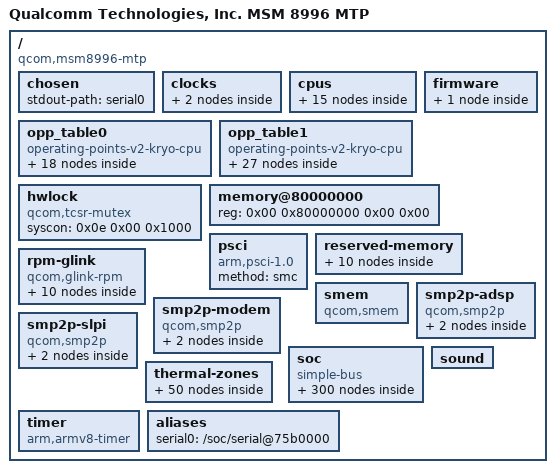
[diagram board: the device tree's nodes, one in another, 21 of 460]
/dts-v1/;

/ {
	interrupt-parent = <0x01>;
	#address-cells = <0x02>;
	#size-cells = <0x02>;
	model = "Qualcomm Technologies, Inc. MSM 8996 MTP";
	compatible = "qcom,msm8996-mtp";

	chosen {
		stdout-path = "serial0";
	};

	clocks {

		xo-board {
			compatible = "fixed-clock";
			#clock-cells = <0x00>;
			clock-frequency = <0x124f800>;
			clock-output-names = "xo_board";
			phandle = <0x1d>;
		};

		sleep-clk {
			compatible = "fixed-clock";
			#clock-cells = <0x00>;
			clock-frequency = <0x7ffc>;
			clock-output-names = "sleep_clk";
			phandle = <0x78>;
		};
	};

	cpus {
		#address-cells = <0x02>;
		#size-cells = <0x00>;

		cpu@0 {
			device_type = "cpu";
			compatible = "qcom,kryo";
			reg = <0x00 0x00>;
			enable-method = "psci";
			cpu-idle-states = <0x02>;
			capacity-dmips-mhz = <0x400>;
			clocks = <0x03 0x00>;
			operating-points-v2 = <0x04>;
			#cooling-cells = <0x02>;
			next-level-cache = <0x05>;
			phandle = <0x08>;

			l2-cache {
				compatible = "cache";
				cache-level = <0x02>;
				phandle = <0x05>;
			};
		};

		cpu@1 {
			device_type = "cpu";
			compatible = "qcom,kryo";
			reg = <0x00 0x01>;
			enable-method = "psci";
			cpu-idle-states = <0x02>;
			capacity-dmips-mhz = <0x400>;
			clocks = <0x03 0x00>;
			operating-points-v2 = <0x04>;
			#cooling-cells = <0x02>;
			next-level-cache = <0x05>;
			phandle = <0x09>;
		};

		cpu@100 {
			device_type = "cpu";
			compatible = "qcom,kryo";
			reg = <0x00 0x100>;
			enable-method = "psci";
			cpu-idle-states = <0x02>;
			capacity-dmips-mhz = <0x400>;
			clocks = <0x03 0x01>;
			operating-points-v2 = <0x06>;
			#cooling-cells = <0x02>;
			next-level-cache = <0x07>;
			phandle = <0x0a>;

			l2-cache {
				compatible = "cache";
				cache-level = <0x02>;
				phandle = <0x07>;
			};
		};

		cpu@101 {
			device_type = "cpu";
			compatible = "qcom,kryo";
			reg = <0x00 0x101>;
			enable-method = "psci";
			cpu-idle-states = <0x02>;
			capacity-dmips-mhz = <0x400>;
			clocks = <0x03 0x01>;
			operating-points-v2 = <0x06>;
			#cooling-cells = <0x02>;
			next-level-cache = <0x07>;
			phandle = <0x0b>;
		};

		cpu-map {

			cluster0 {

				core0 {
					cpu = <0x08>;
				};

				core1 {
					cpu = <0x09>;
				};
			};

			cluster1 {

				core0 {
					cpu = <0x0a>;
				};

				core1 {
					cpu = <0x0b>;
				};
			};
		};

		idle-states {
			entry-method = "psci";

			cpu-sleep-0 {
				compatible = "arm,idle-state";
				idle-state-name = "standalone-power-collapse";
				arm,psci-suspend-param = <0x04>;
				entry-latency-us = <0x82>;
				exit-latency-us = <0x50>;
				min-residency-us = <0x12c>;
				phandle = <0x02>;
			};
		};
	};

	opp_table0 {
		compatible = "operating-points-v2-kryo-cpu";
		nvmem-cells = <0x0c>;
		opp-shared;
		phandle = <0x04>;

		opp-307200000 {
			opp-hz = <0x00 0x124f8000>;
			opp-supported-hw = <0x07>;
			clock-latency-ns = <0x30d40>;
		};

		opp-422400000 {
			opp-hz = <0x00 0x192d5000>;
			opp-supported-hw = <0x07>;
			clock-latency-ns = <0x30d40>;
		};

		opp-480000000 {
			opp-hz = <0x00 0x1c9c3800>;
			opp-supported-hw = <0x07>;
			clock-latency-ns = <0x30d40>;
		};

		opp-556800000 {
			opp-hz = <0x00 0x21301800>;
			opp-supported-hw = <0x07>;
			clock-latency-ns = <0x30d40>;
		};

		opp-652800000 {
			opp-hz = <0x00 0x26e8f000>;
			opp-supported-hw = <0x07>;
			clock-latency-ns = <0x30d40>;
		};

		opp-729600000 {
			opp-hz = <0x00 0x2b7cd000>;
			opp-supported-hw = <0x07>;
			clock-latency-ns = <0x30d40>;
		};

		opp-844800000 {
			opp-hz = <0x00 0x325aa000>;
			opp-supported-hw = <0x07>;
			clock-latency-ns = <0x30d40>;
		};

		opp-960000000 {
			opp-hz = <0x00 0x39387000>;
			opp-supported-hw = <0x07>;
			clock-latency-ns = <0x30d40>;
		};

		opp-1036800000 {
			opp-hz = <0x00 0x3dcc5000>;
			opp-supported-hw = <0x07>;
			clock-latency-ns = <0x30d40>;
		};

		opp-1113600000 {
			opp-hz = <0x00 0x42603000>;
			opp-supported-hw = <0x07>;
			clock-latency-ns = <0x30d40>;
		};

		opp-1190400000 {
			opp-hz = <0x00 0x46f41000>;
			opp-supported-hw = <0x07>;
			clock-latency-ns = <0x30d40>;
		};

		opp-1228800000 {
			opp-hz = <0x00 0x493e0000>;
			opp-supported-hw = <0x07>;
			clock-latency-ns = <0x30d40>;
		};

		opp-1324800000 {
			opp-hz = <0x00 0x4ef6d800>;
			opp-supported-hw = <0x05>;
			clock-latency-ns = <0x30d40>;
		};

		opp-1363200000 {
			opp-hz = <0x00 0x5140c800>;
			opp-supported-hw = <0x02>;
			clock-latency-ns = <0x30d40>;
		};

		opp-1401600000 {
			opp-hz = <0x00 0x538ab800>;
			opp-supported-hw = <0x05>;
			clock-latency-ns = <0x30d40>;
		};

		opp-1478400000 {
			opp-hz = <0x00 0x581e9800>;
			opp-supported-hw = <0x01>;
			clock-latency-ns = <0x30d40>;
		};

		opp-1497600000 {
			opp-hz = <0x00 0x59439000>;
			opp-supported-hw = <0x04>;
			clock-latency-ns = <0x30d40>;
		};

		opp-1593600000 {
			opp-hz = <0x00 0x5efc6800>;
			opp-supported-hw = <0x01>;
			clock-latency-ns = <0x30d40>;
		};
	};

	opp_table1 {
		compatible = "operating-points-v2-kryo-cpu";
		nvmem-cells = <0x0c>;
		opp-shared;
		phandle = <0x06>;

		opp-307200000 {
			opp-hz = <0x00 0x124f8000>;
			opp-supported-hw = <0x07>;
			clock-latency-ns = <0x30d40>;
		};

		opp-403200000 {
			opp-hz = <0x00 0x18085800>;
			opp-supported-hw = <0x07>;
			clock-latency-ns = <0x30d40>;
		};

		opp-480000000 {
			opp-hz = <0x00 0x1c9c3800>;
			opp-supported-hw = <0x07>;
			clock-latency-ns = <0x30d40>;
		};

		opp-556800000 {
			opp-hz = <0x00 0x21301800>;
			opp-supported-hw = <0x07>;
			clock-latency-ns = <0x30d40>;
		};

		opp-652800000 {
			opp-hz = <0x00 0x26e8f000>;
			opp-supported-hw = <0x07>;
			clock-latency-ns = <0x30d40>;
		};

		opp-729600000 {
			opp-hz = <0x00 0x2b7cd000>;
			opp-supported-hw = <0x07>;
			clock-latency-ns = <0x30d40>;
		};

		opp-806400000 {
			opp-hz = <0x00 0x3010b000>;
			opp-supported-hw = <0x07>;
			clock-latency-ns = <0x30d40>;
		};

		opp-883200000 {
			opp-hz = <0x00 0x34a49000>;
			opp-supported-hw = <0x07>;
			clock-latency-ns = <0x30d40>;
		};

		opp-940800000 {
			opp-hz = <0x00 0x38137800>;
			opp-supported-hw = <0x07>;
			clock-latency-ns = <0x30d40>;
		};

		opp-1036800000 {
			opp-hz = <0x00 0x3dcc5000>;
			opp-supported-hw = <0x07>;
			clock-latency-ns = <0x30d40>;
		};

		opp-1113600000 {
			opp-hz = <0x00 0x42603000>;
			opp-supported-hw = <0x07>;
			clock-latency-ns = <0x30d40>;
		};

		opp-1190400000 {
			opp-hz = <0x00 0x46f41000>;
			opp-supported-hw = <0x07>;
			clock-latency-ns = <0x30d40>;
		};

		opp-1248000000 {
			opp-hz = <0x00 0x4a62f800>;
			opp-supported-hw = <0x07>;
			clock-latency-ns = <0x30d40>;
		};

		opp-1324800000 {
			opp-hz = <0x00 0x4ef6d800>;
			opp-supported-hw = <0x07>;
			clock-latency-ns = <0x30d40>;
		};

		opp-1401600000 {
			opp-hz = <0x00 0x538ab800>;
			opp-supported-hw = <0x07>;
			clock-latency-ns = <0x30d40>;
		};

		opp-1478400000 {
			opp-hz = <0x00 0x581e9800>;
			opp-supported-hw = <0x07>;
			clock-latency-ns = <0x30d40>;
		};

		opp-1555200000 {
			opp-hz = <0x00 0x5cb27800>;
			opp-supported-hw = <0x07>;
			clock-latency-ns = <0x30d40>;
		};

		opp-1632000000 {
			opp-hz = <0x00 0x61465800>;
			opp-supported-hw = <0x07>;
			clock-latency-ns = <0x30d40>;
		};

		opp-1708800000 {
			opp-hz = <0x00 0x65da3800>;
			opp-supported-hw = <0x07>;
			clock-latency-ns = <0x30d40>;
		};

		opp-1785600000 {
			opp-hz = <0x00 0x6a6e1800>;
			opp-supported-hw = <0x07>;
			clock-latency-ns = <0x30d40>;
		};

		opp-1804800000 {
			opp-hz = <0x00 0x6b931000>;
			opp-supported-hw = <0x06>;
			clock-latency-ns = <0x30d40>;
		};

		opp-1824000000 {
			opp-hz = <0x00 0x6cb80800>;
			opp-supported-hw = <0x01>;
			clock-latency-ns = <0x30d40>;
		};

		opp-1900800000 {
			opp-hz = <0x00 0x714be800>;
			opp-supported-hw = <0x04>;
			clock-latency-ns = <0x30d40>;
		};

		opp-1920000000 {
			opp-hz = <0x00 0x7270e000>;
			opp-supported-hw = <0x01>;
			clock-latency-ns = <0x30d40>;
		};

		opp-1996800000 {
			opp-hz = <0x00 0x7704c000>;
			opp-supported-hw = <0x01>;
			clock-latency-ns = <0x30d40>;
		};

		opp-2073600000 {
			opp-hz = <0x00 0x7b98a000>;
			opp-supported-hw = <0x01>;
			clock-latency-ns = <0x30d40>;
		};

		opp-2150400000 {
			opp-hz = <0x00 0x802c8000>;
			opp-supported-hw = <0x01>;
			clock-latency-ns = <0x30d40>;
		};
	};

	firmware {

		scm {
			compatible = "qcom,scm-msm8996";
			qcom,dload-mode = <0x0d 0x13000>;
		};
	};

	hwlock {
		compatible = "qcom,tcsr-mutex";
		syscon = <0x0e 0x00 0x1000>;
		#hwlock-cells = <0x01>;
		phandle = <0x13>;
	};

	memory@80000000 {
		device_type = "memory";
		reg = <0x00 0x80000000 0x00 0x00>;
	};

	psci {
		compatible = "arm,psci-1.0";
		method = "smc";
	};

	reserved-memory {
		#address-cells = <0x02>;
		#size-cells = <0x02>;
		ranges;

		mba@91500000 {
			reg = <0x00 0x91500000 0x00 0x200000>;
			no-map;
			phandle = <0x79>;
		};

		slpi@90b00000 {
			reg = <0x00 0x90b00000 0x00 0xa00000>;
			no-map;
			phandle = <0x7a>;
		};

		venus@90400000 {
			reg = <0x00 0x90400000 0x00 0x700000>;
			no-map;
			phandle = <0x33>;
		};

		adsp@8ea00000 {
			reg = <0x00 0x8ea00000 0x00 0x1a00000>;
			no-map;
			phandle = <0x6f>;
		};

		mpss@88800000 {
			reg = <0x00 0x88800000 0x00 0x6200000>;
			no-map;
			phandle = <0x7b>;
		};

		smem-mem@86000000 {
			reg = <0x00 0x86000000 0x00 0x200000>;
			no-map;
			phandle = <0x12>;
		};

		memory@85800000 {
			reg = <0x00 0x85800000 0x00 0x800000>;
			no-map;
		};

		memory@86200000 {
			reg = <0x00 0x86200000 0x00 0x2600000>;
			no-map;
		};

		rmtfs@86700000 {
			compatible = "qcom,rmtfs-mem";
			size = <0x00 0x200000>;
			alloc-ranges = <0x00 0xa0000000 0x00 0x2000000>;
			no-map;
			qcom,client-id = <0x01>;
			qcom,vmid = <0x0f>;
		};

		gpu@8f200000 {
			compatible = "shared-dma-pool";
			reg = <0x00 0x90b00000 0x00 0xa00000>;
			no-map;
			phandle = <0x22>;
		};
	};

	rpm-glink {
		compatible = "qcom,glink-rpm";
		interrupts = <0x00 0xa8 0x01>;
		qcom,rpm-msg-ram = <0x0f>;
		mboxes = <0x10 0x00>;

		rpm-requests {
			compatible = "qcom,rpm-msm8996";
			qcom,glink-channels = "rpm_requests";
			phandle = <0x7c>;

			qcom,rpmcc {
				compatible = "qcom,rpmcc-msm8996";
				#clock-cells = <0x01>;
				phandle = <0x15>;
			};

			power-controller {
				compatible = "qcom,msm8996-rpmpd";
				#power-domain-cells = <0x01>;
				operating-points-v2 = <0x11>;
				phandle = <0x71>;

				opp-table {
					compatible = "operating-points-v2";
					phandle = <0x11>;

					opp1 {
						opp-level = <0x01>;
						phandle = <0x7d>;
					};

					opp2 {
						opp-level = <0x02>;
						phandle = <0x7e>;
					};

					opp3 {
						opp-level = <0x03>;
						phandle = <0x7f>;
					};

					opp4 {
						opp-level = <0x04>;
						phandle = <0x80>;
					};

					opp5 {
						opp-level = <0x05>;
						phandle = <0x81>;
					};

					opp6 {
						opp-level = <0x06>;
						phandle = <0x82>;
					};
				};
			};
		};
	};

	smem {
		compatible = "qcom,smem";
		memory-region = <0x12>;
		hwlocks = <0x13 0x03>;
	};

	smp2p-adsp {
		compatible = "qcom,smp2p";
		qcom,smem = <0x1bb 0x1ad>;
		interrupts = <0x00 0x9e 0x01>;
		mboxes = <0x10 0x0a>;
		qcom,local-pid = <0x00>;
		qcom,remote-pid = <0x02>;

		master-kernel {
			qcom,entry-name = "master-kernel";
			#qcom,smem-state-cells = <0x01>;
			phandle = <0x70>;
		};

		slave-kernel {
			qcom,entry-name = "slave-kernel";
			interrupt-controller;
			#interrupt-cells = <0x02>;
			phandle = <0x6e>;
		};
	};

	smp2p-modem {
		compatible = "qcom,smp2p";
		qcom,smem = <0x1b3 0x1ac>;
		interrupts = <0x00 0x1c3 0x01>;
		mboxes = <0x10 0x0e>;
		qcom,local-pid = <0x00>;
		qcom,remote-pid = <0x01>;

		master-kernel {
			qcom,entry-name = "master-kernel";
			#qcom,smem-state-cells = <0x01>;
			phandle = <0x83>;
		};

		slave-kernel {
			qcom,entry-name = "slave-kernel";
			interrupt-controller;
			#interrupt-cells = <0x02>;
			phandle = <0x84>;
		};
	};

	smp2p-slpi {
		compatible = "qcom,smp2p";
		qcom,smem = <0x1e1 0x1ae>;
		interrupts = <0x00 0xb2 0x01>;
		mboxes = <0x10 0x1a>;
		qcom,local-pid = <0x00>;
		qcom,remote-pid = <0x03>;

		slave-kernel {
			qcom,entry-name = "slave-kernel";
			interrupt-controller;
			#interrupt-cells = <0x02>;
			phandle = <0x85>;
		};

		master-kernel {
			qcom,entry-name = "master-kernel";
			#qcom,smem-state-cells = <0x01>;
			phandle = <0x86>;
		};
	};

	soc {
		#address-cells = <0x01>;
		#size-cells = <0x01>;
		ranges = <0x00 0x00 0x00 0xffffffff>;
		compatible = "simple-bus";
		phandle = <0x87>;

		phy@34000 {
			compatible = "qcom,msm8996-qmp-pcie-phy";
			reg = <0x34000 0x488>;
			#clock-cells = <0x01>;
			#address-cells = <0x01>;
			#size-cells = <0x01>;
			ranges;
			clocks = <0x14 0xc0 0x14 0xbf 0x14 0xd8>;
			clock-names = "aux\0cfg_ahb\0ref";
			resets = <0x14 0x55 0x14 0x65 0x14 0x66>;
			reset-names = "phy\0common\0cfg";
			status = "disabled";
			phandle = <0x88>;

			phy@35000 {
				reg = <0x35000 0x130 0x35200 0x200 0x35400 0x1dc>;
				#phy-cells = <0x00>;
				clock-output-names = "pcie_0_pipe_clk_src";
				clocks = <0x14 0xb4>;
				clock-names = "pipe0";
				resets = <0x14 0x50>;
				reset-names = "lane0";
				phandle = <0x24>;
			};

			phy@36000 {
				reg = <0x36000 0x130 0x36200 0x200 0x36400 0x1dc>;
				#phy-cells = <0x00>;
				clock-output-names = "pcie_1_pipe_clk_src";
				clocks = <0x14 0xb9>;
				clock-names = "pipe1";
				resets = <0x14 0x52>;
				reset-names = "lane1";
				phandle = <0x27>;
			};

			phy@37000 {
				reg = <0x37000 0x130 0x37200 0x200 0x37400 0x1dc>;
				#phy-cells = <0x00>;
				clock-output-names = "pcie_2_pipe_clk_src";
				clocks = <0x14 0xbe>;
				clock-names = "pipe2";
				resets = <0x14 0x54>;
				reset-names = "lane2";
				phandle = <0x2a>;
			};
		};

		sram@68000 {
			compatible = "qcom,rpm-msg-ram";
			reg = <0x68000 0x6000>;
			phandle = <0x0f>;
		};

		qfprom@74000 {
			compatible = "qcom,qfprom";
			reg = <0x74000 0x8ff>;
			#address-cells = <0x01>;
			#size-cells = <0x01>;

			hstx_trim@24e {
				reg = <0x24e 0x02>;
				bits = <0x05 0x04>;
				phandle = <0x54>;
			};

			hstx_trim@24f {
				reg = <0x24f 0x01>;
				bits = <0x01 0x04>;
				phandle = <0x55>;
			};

			speedbin@133 {
				reg = <0x133 0x01>;
				bits = <0x05 0x03>;
				phandle = <0x0c>;
			};
		};

		rng@83000 {
			compatible = "qcom,prng-ee";
			reg = <0x83000 0x1000>;
			clocks = <0x14 0x98>;
			clock-names = "core";
			phandle = <0x89>;
		};

		clock-controller@300000 {
			compatible = "qcom,gcc-msm8996";
			#clock-cells = <0x01>;
			#reset-cells = <0x01>;
			#power-domain-cells = <0x01>;
			reg = <0x300000 0x90000>;
			clocks = <0x15 0x4a>;
			clock-names = "cxo2";
			phandle = <0x14>;
		};

		thermal-sensor@4a9000 {
			compatible = "qcom,msm8996-tsens\0qcom,tsens-v2";
			reg = <0x4a9000 0x1000 0x4a8000 0x1000>;
			#qcom,sensors = <0x0d>;
			interrupts = <0x00 0x1ca 0x04 0x00 0x1bd 0x04>;
			interrupt-names = "uplow\0critical";
			#thermal-sensor-cells = <0x01>;
			phandle = <0x73>;
		};

		thermal-sensor@4ad000 {
			compatible = "qcom,msm8996-tsens\0qcom,tsens-v2";
			reg = <0x4ad000 0x1000 0x4ac000 0x1000>;
			#qcom,sensors = <0x08>;
			interrupts = <0x00 0xb8 0x04 0x00 0x1ae 0x04>;
			interrupt-names = "uplow\0critical";
			#thermal-sensor-cells = <0x01>;
			phandle = <0x74>;
		};

		syscon@740000 {
			compatible = "syscon";
			reg = <0x740000 0x40000>;
			phandle = <0x0e>;
		};

		syscon@7a0000 {
			compatible = "qcom,tcsr-msm8996\0syscon";
			reg = <0x7a0000 0x18000>;
			phandle = <0x0d>;
		};

		clock-controller@8c0000 {
			compatible = "qcom,mmcc-msm8996";
			#clock-cells = <0x01>;
			#reset-cells = <0x01>;
			#power-domain-cells = <0x01>;
			reg = <0x8c0000 0x40000>;
			assigned-clocks = <0x16 0x0f 0x16 0x03 0x16 0x07 0x16 0x09 0x16 0x0b>;
			assigned-clock-rates = <0x25317c00 0x30479e80 0x3a699d00 0x39387000 0x312c8040>;
			phandle = <0x16>;
		};

		mdss@900000 {
			compatible = "qcom,mdss";
			reg = <0x900000 0x1000 0x9b0000 0x1040 0x9b8000 0x1040>;
			reg-names = "mdss_phys\0vbif_phys\0vbif_nrt_phys";
			power-domains = <0x16 0x0d>;
			interrupts = <0x00 0x53 0x04>;
			interrupt-controller;
			#interrupt-cells = <0x01>;
			clocks = <0x16 0x74>;
			clock-names = "iface";
			#address-cells = <0x01>;
			#size-cells = <0x01>;
			ranges;
			status = "disabled";
			phandle = <0x17>;

			mdp@901000 {
				compatible = "qcom,mdp5";
				reg = <0x901000 0x90000>;
				reg-names = "mdp_phys";
				interrupt-parent = <0x17>;
				interrupts = <0x00 0x04>;
				clocks = <0x16 0x74 0x16 0x76 0x16 0x79 0x16 0x5c 0x16 0x7b>;
				clock-names = "iface\0bus\0core\0iommu\0vsync";
				iommus = <0x18 0x00>;
				assigned-clocks = <0x16 0x79 0x16 0x7b>;
				assigned-clock-rates = <0x11e1a300 0x124f800>;
				phandle = <0x8a>;

				ports {
					#address-cells = <0x01>;
					#size-cells = <0x00>;

					port@0 {
						reg = <0x00>;

						endpoint {
							remote-endpoint = <0x19>;
							phandle = <0x1f>;
						};
					};

					port@1 {
						reg = <0x01>;

						endpoint {
							remote-endpoint = <0x1a>;
							phandle = <0x1c>;
						};
					};
				};
			};

			dsi@994000 {
				compatible = "qcom,mdss-dsi-ctrl";
				reg = <0x994000 0x400>;
				reg-names = "dsi_ctrl";
				interrupt-parent = <0x17>;
				interrupts = <0x04 0x04>;
				clocks = <0x16 0x79 0x16 0x7d 0x16 0x74 0x16 0x76 0x16 0x41 0x16 0x77 0x16 0x7f>;
				clock-names = "mdp_core\0byte\0iface\0bus\0core_mmss\0pixel\0core";
				phys = <0x1b>;
				phy-names = "dsi";
				status = "disabled";
				#address-cells = <0x01>;
				#size-cells = <0x00>;
				phandle = <0x8b>;

				ports {
					#address-cells = <0x01>;
					#size-cells = <0x00>;

					port@0 {
						reg = <0x00>;

						endpoint {
							remote-endpoint = <0x1c>;
							phandle = <0x1a>;
						};
					};

					port@1 {
						reg = <0x01>;

						endpoint {
							phandle = <0x8c>;
						};
					};
				};
			};

			dsi-phy@994400 {
				compatible = "qcom,dsi-phy-14nm";
				reg = <0x994400 0x100 0x994500 0x300 0x994800 0x188>;
				reg-names = "dsi_phy\0dsi_phy_lane\0dsi_pll";
				#clock-cells = <0x01>;
				#phy-cells = <0x00>;
				clocks = <0x16 0x74 0x1d>;
				clock-names = "iface\0ref";
				status = "disabled";
				phandle = <0x1b>;
			};

			hdmi-tx@9a0000 {
				compatible = "qcom,hdmi-tx-8996";
				reg = <0x9a0000 0x50c 0x70000 0x6158 0x9e0000 0xfff>;
				reg-names = "core_physical\0qfprom_physical\0hdcp_physical";
				interrupt-parent = <0x17>;
				interrupts = <0x08 0x04>;
				clocks = <0x16 0x79 0x16 0x74 0x16 0x7c 0x16 0x75 0x16 0x7a>;
				clock-names = "mdp_core\0iface\0core\0alt_iface\0extp";
				phys = <0x1e>;
				phy-names = "hdmi_phy";
				#sound-dai-cells = <0x01>;
				status = "okay";
				phandle = <0x8d>;

				ports {
					#address-cells = <0x01>;
					#size-cells = <0x00>;

					port@0 {
						reg = <0x00>;

						endpoint {
							remote-endpoint = <0x1f>;
							phandle = <0x19>;
						};
					};
				};
			};

			hdmi-phy@9a0600 {
				#phy-cells = <0x00>;
				compatible = "qcom,hdmi-phy-8996";
				reg = <0x9a0600 0x1c4 0x9a0a00 0x124 0x9a0c00 0x124 0x9a0e00 0x124 0x9a1000 0x124 0x9a1200 0xc8>;
				reg-names = "hdmi_pll\0hdmi_tx_l0\0hdmi_tx_l1\0hdmi_tx_l2\0hdmi_tx_l3\0hdmi_phy";
				clocks = <0x16 0x74 0x14 0xd6>;
				clock-names = "iface\0ref";
				status = "okay";
				phandle = <0x1e>;
			};
		};

		gpu@b00000 {
			compatible = "qcom,adreno-530.2\0qcom,adreno";
			#stream-id-cells = <0x10>;
			reg = <0xb00000 0x3f000>;
			reg-names = "kgsl_3d0_reg_memory";
			interrupts = <0x00 0x12c 0x04>;
			clocks = <0x16 0x66 0x16 0x68 0x16 0x67 0x14 0xa8 0x14 0x5a>;
			clock-names = "core\0iface\0rbbmtimer\0mem\0mem_iface";
			power-domains = <0x16 0x0e>;
			iommus = <0x20 0x00>;
			nvmem-cells = <0x0c>;
			nvmem-cell-names = "speed_bin";
			operating-points-v2 = <0x21>;
			status = "disabled";
			#cooling-cells = <0x02>;
			phandle = <0x76>;

			opp-table {
				compatible = "operating-points-v2";
				phandle = <0x21>;

				opp-624000000 {
					opp-hz = <0x00 0x25317c00>;
					opp-supported-hw = <0x09>;
				};

				opp-560000000 {
					opp-hz = <0x00 0x2160ec00>;
					opp-supported-hw = <0x0d>;
				};

				opp-510000000 {
					opp-hz = <0x00 0x1e65fb80>;
					opp-supported-hw = <0xff>;
				};

				opp-401800000 {
					opp-hz = <0x00 0x17f2fb40>;
					opp-supported-hw = <0xff>;
				};

				opp-315000000 {
					opp-hz = <0x00 0x12c684c0>;
					opp-supported-hw = <0xff>;
				};

				opp-214000000 {
					opp-hz = <0x00 0xcc16180>;
					opp-supported-hw = <0xff>;
				};

				opp-133000000 {
					opp-hz = <0x00 0x7ed6b40>;
					opp-supported-hw = <0xff>;
				};
			};

			zap-shader {
				memory-region = <0x22>;
			};
		};

		pinctrl@1010000 {
			compatible = "qcom,msm8996-pinctrl";
			reg = <0x1010000 0x300000>;
			interrupts = <0x00 0xd0 0x04>;
			gpio-controller;
			gpio-ranges = <0x23 0x00 0x00 0x96>;
			#gpio-cells = <0x02>;
			interrupt-controller;
			#interrupt-cells = <0x02>;
			phandle = <0x23>;

			blsp1-spi1-default {
				phandle = <0x5b>;

				spi {
					pins = "gpio0\0gpio1\0gpio3";
					function = "blsp_spi1";
					drive-strength = <0x0c>;
					bias-disable;
				};

				cs {
					pins = "gpio2";
					function = "gpio";
					drive-strength = <0x10>;
					bias-disable;
					output-high;
				};
			};

			blsp1-spi1-sleep {
				pins = "gpio0\0gpio1\0gpio2\0gpio3";
				function = "gpio";
				drive-strength = <0x02>;
				bias-pull-down;
				phandle = <0x5c>;
			};

			blsp2-uart1-2pins {
				pins = "gpio4\0gpio5";
				function = "blsp_uart8";
				drive-strength = <0x10>;
				bias-disable;
				phandle = <0x8e>;
			};

			blsp2-uart1-2pins-sleep {
				pins = "gpio4\0gpio5";
				function = "gpio";
				drive-strength = <0x02>;
				bias-disable;
				phandle = <0x8f>;
			};

			blsp2-i2c2 {
				pins = "gpio6\0gpio7";
				function = "blsp_i2c8";
				drive-strength = <0x10>;
				bias-disable;
				phandle = <0x62>;
			};

			blsp2-i2c2-sleep {
				pins = "gpio6\0gpio7";
				function = "gpio";
				drive-strength = <0x02>;
				bias-disable;
				phandle = <0x63>;
			};

			cci0-default {
				pins = "gpio17\0gpio18";
				function = "cci_i2c";
				drive-strength = <0x10>;
				bias-disable;
				phandle = <0x30>;
			};

			camera-rear-default {
				phandle = <0x90>;

				mclk0 {
					pins = "gpio13";
					function = "cam_mclk";
					drive-strength = <0x10>;
					bias-disable;
					phandle = <0x91>;
				};

				rst {
					pins = "gpio25";
					function = "gpio";
					drive-strength = <0x10>;
					bias-disable;
					phandle = <0x92>;
				};

				pwdn {
					pins = "gpio26";
					function = "gpio";
					drive-strength = <0x10>;
					bias-disable;
					phandle = <0x93>;
				};
			};

			cci1-default {
				pins = "gpio19\0gpio20";
				function = "cci_i2c";
				drive-strength = <0x10>;
				bias-disable;
				phandle = <0x31>;
			};

			camera-board-default {
				phandle = <0x94>;

				mclk1 {
					pins = "gpio14";
					function = "cam_mclk";
					drive-strength = <0x10>;
					bias-disable;
				};

				pwdn {
					pins = "gpio98";
					function = "gpio";
					drive-strength = <0x10>;
					bias-disable;
				};

				rst {
					pins = "gpio104";
					function = "gpio";
					drive-strength = <0x10>;
					bias-disable;
				};
			};

			camera-front-default {
				phandle = <0x95>;

				mclk2 {
					pins = "gpio15";
					function = "cam_mclk";
					drive-strength = <0x10>;
					bias-disable;
					phandle = <0x96>;
				};

				rst {
					pins = "gpio23";
					function = "gpio";
					drive-strength = <0x10>;
					bias-disable;
					phandle = <0x97>;
				};

				pwdn {
					pins = "gpio133";
					function = "gpio";
					drive-strength = <0x10>;
					bias-disable;
				};
			};

			pcie0-state-on {
				phandle = <0x25>;

				perst {
					pins = "gpio35";
					function = "gpio";
					drive-strength = <0x02>;
					bias-pull-down;
				};

				clkreq {
					pins = "gpio36";
					function = "pci_e0";
					drive-strength = <0x02>;
					bias-pull-up;
				};

				wake {
					pins = "gpio37";
					function = "gpio";
					drive-strength = <0x02>;
					bias-pull-up;
				};
			};

			pcie0-state-off {
				phandle = <0x26>;

				perst {
					pins = "gpio35";
					function = "gpio";
					drive-strength = <0x02>;
					bias-pull-down;
				};

				clkreq {
					pins = "gpio36";
					function = "gpio";
					drive-strength = <0x02>;
					bias-disable;
				};

				wake {
					pins = "gpio37";
					function = "gpio";
					drive-strength = <0x02>;
					bias-disable;
				};
			};

			blsp1-i2c2-default {
				pins = "gpio47\0gpio48";
				function = "blsp_i2c3";
				drive-strength = <0x10>;
				bias-disable = <0x00>;
				phandle = <0x5d>;
			};

			blsp1-i2c2-sleep {
				pins = "gpio47\0gpio48";
				function = "gpio";
				drive-strength = <0x02>;
				bias-disable = <0x00>;
				phandle = <0x5e>;
			};

			blsp2-uart2-4pins {
				pins = "gpio49\0gpio50\0gpio51\0gpio52";
				function = "blsp_uart9";
				drive-strength = <0x10>;
				bias-disable;
				phandle = <0x98>;
			};

			blsp2-uart2-4pins-sleep {
				pins = "gpio49\0gpio50\0gpio51\0gpio52";
				function = "blsp_uart9";
				drive-strength = <0x02>;
				bias-disable;
				phandle = <0x99>;
			};

			wcd-intr-default {
				pins = "gpio54";
				function = "gpio";
				drive-strength = <0x02>;
				bias-pull-down;
				input-enable;
				phandle = <0x6c>;
			};

			blsp2-i2c1 {
				pins = "gpio55\0gpio56";
				function = "blsp_i2c7";
				drive-strength = <0x10>;
				bias-disable;
				phandle = <0x5f>;
			};

			blsp2-i2c0-sleep {
				pins = "gpio55\0gpio56";
				function = "gpio";
				drive-strength = <0x02>;
				bias-disable;
				phandle = <0x60>;
			};

			blsp2-i2c5 {
				pins = "gpio60\0gpio61";
				function = "blsp_i2c11";
				drive-strength = <0x02>;
				bias-disable;
				phandle = <0x64>;
			};

			cdc-reset-active {
				pins = "gpio64";
				function = "gpio";
				drive-strength = <0x10>;
				bias-pull-down;
				output-high;
				phandle = <0x6b>;
			};

			cdc-reset-sleep {
				pins = "gpio64";
				function = "gpio";
				drive-strength = <0x10>;
				bias-disable;
				output-low;
				phandle = <0x9a>;
			};

			blsp2-spi5-default {
				phandle = <0x67>;

				spi {
					pins = "gpio85\0gpio86\0gpio88";
					function = "blsp_spi12";
					drive-strength = <0x0c>;
					bias-disable;
				};

				cs {
					pins = "gpio87";
					function = "gpio";
					drive-strength = <0x10>;
					bias-disable;
					output-high;
				};
			};

			blsp2-spi5-sleep {
				pins = "gpio85\0gpio86\0gpio87\0gpio88";
				function = "gpio";
				drive-strength = <0x02>;
				bias-pull-down;
				phandle = <0x68>;
			};

			blsp2-i2c6 {
				pins = "gpio87\0gpio88";
				function = "blsp_i2c12";
				drive-strength = <0x10>;
				bias-disable;
				phandle = <0x65>;
			};

			blsp2-i2c6-sleep {
				pins = "gpio87\0gpio88";
				function = "gpio";
				drive-strength = <0x02>;
				bias-disable;
				phandle = <0x66>;
			};

			pcie1-state-on {
				phandle = <0x28>;

				perst {
					pins = "gpio130";
					function = "gpio";
					drive-strength = <0x02>;
					bias-pull-down;
				};

				clkreq {
					pins = "gpio131";
					function = "pci_e1";
					drive-strength = <0x02>;
					bias-pull-up;
				};

				wake {
					pins = "gpio132";
					function = "gpio";
					drive-strength = <0x02>;
					bias-pull-down;
				};
			};

			pcie1-state-off {
				phandle = <0x29>;

				clkreq {
					pins = "gpio131";
					function = "gpio";
					drive-strength = <0x02>;
					bias-disable;
				};

				wake {
					pins = "gpio132";
					function = "gpio";
					drive-strength = <0x02>;
					bias-disable;
				};
			};

			pcie2-state-on {
				phandle = <0x2b>;

				perst {
					pins = "gpio114";
					function = "gpio";
					drive-strength = <0x02>;
					bias-pull-down;
				};

				clkreq {
					pins = "gpio115";
					function = "pci_e2";
					drive-strength = <0x02>;
					bias-pull-up;
				};

				wake {
					pins = "gpio116";
					function = "gpio";
					drive-strength = <0x02>;
					bias-pull-down;
				};
			};

			pcie2-state-off {
				phandle = <0x2c>;

				clkreq {
					pins = "gpio115";
					function = "gpio";
					drive-strength = <0x02>;
					bias-disable;
				};

				wake {
					pins = "gpio116";
					function = "gpio";
					drive-strength = <0x02>;
					bias-disable;
				};
			};

			sdc1-state-on {
				phandle = <0x56>;

				clk {
					pins = "sdc1_clk";
					bias-disable;
					drive-strength = <0x10>;
				};

				cmd {
					pins = "sdc1_cmd";
					bias-pull-up;
					drive-strength = <0x0a>;
				};

				data {
					pins = "sdc1_data";
					bias-pull-up;
					drive-strength = <0x0a>;
				};

				rclk {
					pins = "sdc1_rclk";
					bias-pull-down;
				};
			};

			sdc1-state-off {
				phandle = <0x57>;

				clk {
					pins = "sdc1_clk";
					bias-disable;
					drive-strength = <0x02>;
				};

				cmd {
					pins = "sdc1_cmd";
					bias-pull-up;
					drive-strength = <0x02>;
				};

				data {
					pins = "sdc1_data";
					bias-pull-up;
					drive-strength = <0x02>;
				};

				rclk {
					pins = "sdc1_rclk";
					bias-pull-down;
				};
			};

			sdc2-clk-on {
				phandle = <0x58>;

				clk {
					pins = "sdc2_clk";
					bias-disable;
					drive-strength = <0x10>;
				};

				cmd {
					pins = "sdc2_cmd";
					bias-pull-up;
					drive-strength = <0x0a>;
				};

				data {
					pins = "sdc2_data";
					bias-pull-up;
					drive-strength = <0x0a>;
				};
			};

			sdc2-clk-off {
				phandle = <0x59>;

				clk {
					pins = "sdc2_clk";
					bias-disable;
					drive-strength = <0x02>;
				};

				cmd {
					pins = "sdc2_cmd";
					bias-pull-up;
					drive-strength = <0x02>;
				};

				data {
					pins = "sdc2_data";
					bias-pull-up;
					drive-strength = <0x02>;
				};
			};
		};

		qcom,spmi@400f000 {
			compatible = "qcom,spmi-pmic-arb";
			reg = <0x400f000 0x1000 0x4400000 0x800000 0x4c00000 0x800000 0x5800000 0x200000 0x400a000 0x2100>;
			reg-names = "core\0chnls\0obsrvr\0intr\0cnfg";
			interrupt-names = "periph_irq";
			interrupts = <0x00 0x146 0x04>;
			qcom,ee = <0x00>;
			qcom,channel = <0x00>;
			#address-cells = <0x02>;
			#size-cells = <0x00>;
			interrupt-controller;
			#interrupt-cells = <0x04>;
			phandle = <0x9b>;
		};

		agnoc@0 {
			power-domains = <0x14 0x00>;
			compatible = "simple-pm-bus";
			#address-cells = <0x01>;
			#size-cells = <0x01>;
			ranges;

			pcie@600000 {
				compatible = "qcom,pcie-msm8996\0snps,dw-pcie";
				status = "disabled";
				power-domains = <0x14 0x05>;
				bus-range = <0x00 0xff>;
				num-lanes = <0x01>;
				reg = <0x600000 0x2000 0xc000000 0xf1d 0xc000f20 0xa8 0xc100000 0x100000>;
				reg-names = "parf\0dbi\0elbi\0config";
				phys = <0x24>;
				phy-names = "pciephy";
				#address-cells = <0x03>;
				#size-cells = <0x02>;
				ranges = <0x1000000 0x00 0xc200000 0xc200000 0x00 0x100000 0x2000000 0x00 0xc300000 0xc300000 0x00 0xd00000>;
				device_type = "pci";
				interrupts = <0x00 0x195 0x04>;
				interrupt-names = "msi";
				#interrupt-cells = <0x01>;
				interrupt-map-mask = <0x00 0x00 0x00 0x07>;
				interrupt-map = <0x00 0x00 0x00 0x01 0x01 0x00 0xf4 0x04 0x00 0x00 0x00 0x02 0x01 0x00 0xf5 0x04 0x00 0x00 0x00 0x03 0x01 0x00 0xf7 0x04 0x00 0x00 0x00 0x04 0x01 0x00 0xf8 0x04>;
				pinctrl-names = "default\0sleep";
				pinctrl-0 = <0x25>;
				pinctrl-1 = <0x26>;
				linux,pci-domain = <0x00>;
				clocks = <0x14 0xb4 0x14 0xb3 0x14 0xb2 0x14 0xb1 0x14 0xb0>;
				clock-names = "pipe\0aux\0cfg\0bus_master\0bus_slave";
				phandle = <0x9c>;
			};

			pcie@608000 {
				compatible = "qcom,pcie-msm8996\0snps,dw-pcie";
				power-domains = <0x14 0x06>;
				bus-range = <0x00 0xff>;
				num-lanes = <0x01>;
				status = "disabled";
				reg = <0x608000 0x2000 0xd000000 0xf1d 0xd000f20 0xa8 0xd100000 0x100000>;
				reg-names = "parf\0dbi\0elbi\0config";
				phys = <0x27>;
				phy-names = "pciephy";
				#address-cells = <0x03>;
				#size-cells = <0x02>;
				ranges = <0x1000000 0x00 0xd200000 0xd200000 0x00 0x100000 0x2000000 0x00 0xd300000 0xd300000 0x00 0xd00000>;
				device_type = "pci";
				interrupts = <0x00 0x19d 0x04>;
				interrupt-names = "msi";
				#interrupt-cells = <0x01>;
				interrupt-map-mask = <0x00 0x00 0x00 0x07>;
				interrupt-map = <0x00 0x00 0x00 0x01 0x01 0x00 0x110 0x04 0x00 0x00 0x00 0x02 0x01 0x00 0x111 0x04 0x00 0x00 0x00 0x03 0x01 0x00 0x112 0x04 0x00 0x00 0x00 0x04 0x01 0x00 0x113 0x04>;
				pinctrl-names = "default\0sleep";
				pinctrl-0 = <0x28>;
				pinctrl-1 = <0x29>;
				linux,pci-domain = <0x01>;
				clocks = <0x14 0xb9 0x14 0xb8 0x14 0xb7 0x14 0xb6 0x14 0xb5>;
				clock-names = "pipe\0aux\0cfg\0bus_master\0bus_slave";
				phandle = <0x9d>;
			};

			pcie@610000 {
				compatible = "qcom,pcie-msm8996\0snps,dw-pcie";
				power-domains = <0x14 0x07>;
				bus-range = <0x00 0xff>;
				num-lanes = <0x01>;
				status = "disabled";
				reg = <0x610000 0x2000 0xe000000 0xf1d 0xe000f20 0xa8 0xe100000 0x100000>;
				reg-names = "parf\0dbi\0elbi\0config";
				phys = <0x2a>;
				phy-names = "pciephy";
				#address-cells = <0x03>;
				#size-cells = <0x02>;
				ranges = <0x1000000 0x00 0xe200000 0xe200000 0x00 0x100000 0x2000000 0x00 0xe300000 0xe300000 0x00 0x1d00000>;
				device_type = "pci";
				interrupts = <0x00 0x1a5 0x04>;
				interrupt-names = "msi";
				#interrupt-cells = <0x01>;
				interrupt-map-mask = <0x00 0x00 0x00 0x07>;
				interrupt-map = <0x00 0x00 0x00 0x01 0x01 0x00 0x8e 0x04 0x00 0x00 0x00 0x02 0x01 0x00 0x8f 0x04 0x00 0x00 0x00 0x03 0x01 0x00 0x90 0x04 0x00 0x00 0x00 0x04 0x01 0x00 0x91 0x04>;
				pinctrl-names = "default\0sleep";
				pinctrl-0 = <0x2b>;
				pinctrl-1 = <0x2c>;
				linux,pci-domain = <0x02>;
				clocks = <0x14 0xbe 0x14 0xbd 0x14 0xbc 0x14 0xbb 0x14 0xba>;
				clock-names = "pipe\0aux\0cfg\0bus_master\0bus_slave";
				phandle = <0x9e>;
			};
		};

		ufshc@624000 {
			compatible = "qcom,ufshc";
			reg = <0x624000 0x2500>;
			interrupts = <0x00 0x109 0x04>;
			phys = <0x2d>;
			phy-names = "ufsphy";
			power-domains = <0x14 0x08>;
			clock-names = "core_clk_src\0core_clk\0bus_clk\0bus_aggr_clk\0iface_clk\0core_clk_unipro_src\0core_clk_unipro\0core_clk_ice\0ref_clk\0tx_lane0_sync_clk\0rx_lane0_sync_clk";
			clocks = <0x14 0x49 0x14 0xc1 0x14 0x52 0x14 0xd1 0x14 0xc2 0x14 0x4a 0x14 0xc8 0x14 0xc9 0x15 0x4a 0x14 0xc5 0x14 0xc6>;
			freq-table-hz = <0x5f5e100 0xbebc200 0x00 0x00 0x00 0x00 0x00 0x00 0x00 0x00 0x8f0d180 0x11e1a300 0x00 0x00 0x00 0x00 0x00 0x00 0x00 0x00 0x00 0x00>;
			lanes-per-direction = <0x01>;
			#reset-cells = <0x01>;
			status = "disabled";
			phandle = <0x2e>;

			ufs_variant {
				compatible = "qcom,ufs_variant";
			};
		};

		phy@627000 {
			compatible = "qcom,msm8996-qmp-ufs-phy";
			reg = <0x627000 0x1c4>;
			#address-cells = <0x01>;
			#size-cells = <0x01>;
			ranges;
			clocks = <0x14 0xd7>;
			clock-names = "ref";
			resets = <0x2e 0x00>;
			reset-names = "ufsphy";
			status = "disabled";
			phandle = <0x9f>;

			phy@627400 {
				reg = <0x627400 0x12c 0x627600 0x200 0x627c00 0x1b4>;
				#phy-cells = <0x00>;
				phandle = <0x2d>;
			};
		};

		camss@a00000 {
			compatible = "qcom,msm8996-camss";
			reg = <0xa34000 0x1000 0xa00030 0x04 0xa35000 0x1000 0xa00038 0x04 0xa36000 0x1000 0xa00040 0x04 0xa30000 0x100 0xa30400 0x100 0xa30800 0x100 0xa30c00 0x100 0xa31000 0x500 0xa00020 0x10 0xa10000 0x1000 0xa14000 0x1000>;
			reg-names = "csiphy0\0csiphy0_clk_mux\0csiphy1\0csiphy1_clk_mux\0csiphy2\0csiphy2_clk_mux\0csid0\0csid1\0csid2\0csid3\0ispif\0csi_clk_mux\0vfe0\0vfe1";
			interrupts = <0x00 0x4e 0x01 0x00 0x4f 0x01 0x00 0x50 0x01 0x00 0x128 0x01 0x00 0x129 0x01 0x00 0x12a 0x01 0x00 0x12b 0x01 0x00 0x135 0x01 0x00 0x13a 0x01 0x00 0x13b 0x01>;
			interrupt-names = "csiphy0\0csiphy1\0csiphy2\0csid0\0csid1\0csid2\0csid3\0ispif\0vfe0\0vfe1";
			power-domains = <0x16 0x08 0x16 0x09>;
			clocks = <0x16 0x81 0x16 0xb9 0x16 0x8c 0x16 0x8d 0x16 0x8e 0x16 0xa6 0x16 0xa5 0x16 0xa7 0x16 0xa9 0x16 0xa8 0x16 0xab 0x16 0xaa 0x16 0xac 0x16 0xae 0x16 0xad 0x16 0xb0 0x16 0xaf 0x16 0xb1 0x16 0xb3 0x16 0xb2 0x16 0xb5 0x16 0xb4 0x16 0xb6 0x16 0xb8 0x16 0xb7 0x16 0x82 0x16 0x99 0x16 0x9f 0x16 0x9b 0x16 0x9a 0x16 0x9c 0x16 0xa0 0x16 0x9e 0x16 0x9d 0x16 0x97 0x16 0x98>;
			clock-names = "top_ahb\0ispif_ahb\0csiphy0_timer\0csiphy1_timer\0csiphy2_timer\0csi0_ahb\0csi0\0csi0_phy\0csi0_pix\0csi0_rdi\0csi1_ahb\0csi1\0csi1_phy\0csi1_pix\0csi1_rdi\0csi2_ahb\0csi2\0csi2_phy\0csi2_pix\0csi2_rdi\0csi3_ahb\0csi3\0csi3_phy\0csi3_pix\0csi3_rdi\0ahb\0vfe0\0csi_vfe0\0vfe0_ahb\0vfe0_stream\0vfe1\0csi_vfe1\0vfe1_ahb\0vfe1_stream\0vfe_ahb\0vfe_axi";
			iommus = <0x2f 0x00 0x2f 0x01 0x2f 0x02 0x2f 0x03>;
			status = "disabled";
			phandle = <0xa0>;

			ports {
				#address-cells = <0x01>;
				#size-cells = <0x00>;
			};
		};

		cci@a0c000 {
			compatible = "qcom,msm8996-cci";
			#address-cells = <0x01>;
			#size-cells = <0x00>;
			reg = <0xa0c000 0x1000>;
			interrupts = <0x00 0x127 0x01>;
			power-domains = <0x16 0x07>;
			clocks = <0x16 0x81 0x16 0x8b 0x16 0x8a 0x16 0x82>;
			clock-names = "camss_top_ahb\0cci_ahb\0cci\0camss_ahb";
			assigned-clocks = <0x16 0x8b 0x16 0x8a>;
			assigned-clock-rates = <0x4c4b400 0x23c3460>;
			pinctrl-names = "default";
			pinctrl-0 = <0x30 0x31>;
			status = "disabled";
			phandle = <0xa1>;

			i2c-bus@0 {
				reg = <0x00>;
				clock-frequency = <0x61a80>;
				#address-cells = <0x01>;
				#size-cells = <0x00>;
				phandle = <0xa2>;
			};

			i2c-bus@1 {
				reg = <0x01>;
				clock-frequency = <0x61a80>;
				#address-cells = <0x01>;
				#size-cells = <0x00>;
				phandle = <0xa3>;
			};
		};

		iommu@b40000 {
			compatible = "qcom,msm8996-smmu-v2\0qcom,adreno-smmu\0qcom,smmu-v2";
			reg = <0xb40000 0x10000>;
			#global-interrupts = <0x01>;
			interrupts = <0x00 0x14e 0x04 0x00 0x149 0x04 0x00 0x14a 0x04>;
			#iommu-cells = <0x01>;
			clocks = <0x16 0x68 0x14 0x5a>;
			clock-names = "iface\0bus";
			power-domains = <0x16 0x03>;
			phandle = <0x20>;
		};

		video-codec@c00000 {
			compatible = "qcom,msm8996-venus";
			reg = <0xc00000 0xff000>;
			interrupts = <0x00 0x11f 0x04>;
			power-domains = <0x16 0x04>;
			clocks = <0x16 0x6e 0x16 0x71 0x16 0x6f 0x16 0x70>;
			clock-names = "core\0iface\0bus\0mbus";
			iommus = <0x32 0x00 0x32 0x01 0x32 0x0a 0x32 0x07 0x32 0x0e 0x32 0x0f 0x32 0x08 0x32 0x09 0x32 0x0b 0x32 0x0c 0x32 0x0d 0x32 0x10 0x32 0x11 0x32 0x21 0x32 0x28 0x32 0x29 0x32 0x2b 0x32 0x2c 0x32 0x2d 0x32 0x31>;
			memory-region = <0x33>;
			status = "disabled";
			phandle = <0xa4>;

			video-decoder {
				compatible = "venus-decoder";
				clocks = <0x16 0x72>;
				clock-names = "core";
				power-domains = <0x16 0x05>;
			};

			video-encoder {
				compatible = "venus-encoder";
				clocks = <0x16 0x73>;
				clock-names = "core";
				power-domains = <0x16 0x06>;
			};
		};

		iommu@d00000 {
			compatible = "qcom,msm8996-smmu-v2\0qcom,smmu-v2";
			reg = <0xd00000 0x10000>;
			#global-interrupts = <0x01>;
			interrupts = <0x00 0x49 0x04 0x00 0x140 0x04 0x00 0x141 0x04>;
			#iommu-cells = <0x01>;
			clocks = <0x16 0x5b 0x16 0x5c>;
			clock-names = "iface\0bus";
			power-domains = <0x16 0x0d>;
			phandle = <0x18>;
		};

		iommu@d40000 {
			compatible = "qcom,msm8996-smmu-v2\0qcom,smmu-v2";
			reg = <0xd40000 0x20000>;
			#global-interrupts = <0x01>;
			interrupts = <0x00 0x11e 0x04 0x00 0x14f 0x04 0x00 0x150 0x04 0x00 0x151 0x04 0x00 0x152 0x04 0x00 0x153 0x04 0x00 0x154 0x04 0x00 0x155 0x04>;
			power-domains = <0x16 0x00>;
			clocks = <0x16 0x62 0x16 0x63>;
			clock-names = "iface\0bus";
			#iommu-cells = <0x01>;
			status = "okay";
			phandle = <0x32>;
		};

		iommu@da0000 {
			compatible = "qcom,msm8996-smmu-v2\0qcom,smmu-v2";
			reg = <0xda0000 0x10000>;
			#global-interrupts = <0x01>;
			interrupts = <0x00 0x4c 0x04 0x00 0x157 0x04 0x00 0x158 0x04>;
			power-domains = <0x16 0x02>;
			clocks = <0x16 0x4e 0x16 0x4f>;
			clock-names = "iface\0bus";
			#iommu-cells = <0x01>;
			phandle = <0x2f>;
		};

		iommu@1600000 {
			compatible = "qcom,msm8996-smmu-v2\0qcom,smmu-v2";
			reg = <0x1600000 0x20000>;
			#iommu-cells = <0x01>;
			power-domains = <0x14 0x03>;
			#global-interrupts = <0x01>;
			interrupts = <0x00 0x194 0x04 0x00 0xe2 0x04 0x00 0x189 0x04 0x00 0x18a 0x04 0x00 0x18b 0x04 0x00 0x18c 0x04 0x00 0x18d 0x04 0x00 0x18e 0x04 0x00 0x18f 0x04 0x00 0x190 0x04 0x00 0x191 0x04 0x00 0x192 0x04 0x00 0x193 0x04>;
			clocks = <0x14 0xdb 0x14 0xdc>;
			clock-names = "iface\0bus";
			phandle = <0x72>;
		};

		stm@3002000 {
			compatible = "arm,coresight-stm\0arm,primecell";
			reg = <0x3002000 0x1000 0x8280000 0x180000>;
			reg-names = "stm-base\0stm-stimulus-base";
			clocks = <0x15 0x08 0x15 0x09>;
			clock-names = "apb_pclk\0atclk";

			out-ports {

				port {

					endpoint {
						remote-endpoint = <0x34>;
						phandle = <0x36>;
					};
				};
			};
		};

		tpiu@3020000 {
			compatible = "arm,coresight-tpiu\0arm,primecell";
			reg = <0x3020000 0x1000>;
			clocks = <0x15 0x08 0x15 0x09>;
			clock-names = "apb_pclk\0atclk";

			in-ports {

				port {

					endpoint {
						remote-endpoint = <0x35>;
						phandle = <0x41>;
					};
				};
			};
		};

		funnel@3021000 {
			compatible = "arm,coresight-dynamic-funnel\0arm,primecell";
			reg = <0x3021000 0x1000>;
			clocks = <0x15 0x08 0x15 0x09>;
			clock-names = "apb_pclk\0atclk";

			in-ports {
				#address-cells = <0x01>;
				#size-cells = <0x00>;

				port@7 {
					reg = <0x07>;

					endpoint {
						remote-endpoint = <0x36>;
						phandle = <0x34>;
					};
				};
			};

			out-ports {

				port {

					endpoint {
						remote-endpoint = <0x37>;
						phandle = <0x3b>;
					};
				};
			};
		};

		funnel@3022000 {
			compatible = "arm,coresight-dynamic-funnel\0arm,primecell";
			reg = <0x3022000 0x1000>;
			clocks = <0x15 0x08 0x15 0x09>;
			clock-names = "apb_pclk\0atclk";

			in-ports {
				#address-cells = <0x01>;
				#size-cells = <0x00>;

				port@6 {
					reg = <0x06>;

					endpoint {
						remote-endpoint = <0x38>;
						phandle = <0x51>;
					};
				};
			};

			out-ports {

				port {

					endpoint {
						remote-endpoint = <0x39>;
						phandle = <0x3c>;
					};
				};
			};
		};

		funnel@3023000 {
			compatible = "arm,coresight-dynamic-funnel\0arm,primecell";
			reg = <0x3023000 0x1000>;
			clocks = <0x15 0x08 0x15 0x09>;
			clock-names = "apb_pclk\0atclk";

			out-ports {

				port {

					endpoint {
						remote-endpoint = <0x3a>;
						phandle = <0x3d>;
					};
				};
			};
		};

		funnel@3025000 {
			compatible = "arm,coresight-dynamic-funnel\0arm,primecell";
			reg = <0x3025000 0x1000>;
			clocks = <0x15 0x08 0x15 0x09>;
			clock-names = "apb_pclk\0atclk";

			in-ports {
				#address-cells = <0x01>;
				#size-cells = <0x00>;

				port@0 {
					reg = <0x00>;

					endpoint {
						remote-endpoint = <0x3b>;
						phandle = <0x37>;
					};
				};

				port@1 {
					reg = <0x01>;

					endpoint {
						remote-endpoint = <0x3c>;
						phandle = <0x39>;
					};
				};

				port@2 {
					reg = <0x02>;

					endpoint {
						remote-endpoint = <0x3d>;
						phandle = <0x3a>;
					};
				};
			};

			out-ports {

				port {

					endpoint {
						remote-endpoint = <0x3e>;
						phandle = <0x42>;
					};
				};
			};
		};

		replicator@3026000 {
			compatible = "arm,coresight-dynamic-replicator\0arm,primecell";
			reg = <0x3026000 0x1000>;
			clocks = <0x15 0x08 0x15 0x09>;
			clock-names = "apb_pclk\0atclk";

			in-ports {

				port {

					endpoint {
						remote-endpoint = <0x3f>;
						phandle = <0x43>;
					};
				};
			};

			out-ports {
				#address-cells = <0x01>;
				#size-cells = <0x00>;

				port@0 {
					reg = <0x00>;

					endpoint {
						remote-endpoint = <0x40>;
						phandle = <0x44>;
					};
				};

				port@1 {
					reg = <0x01>;

					endpoint {
						remote-endpoint = <0x41>;
						phandle = <0x35>;
					};
				};
			};
		};

		etf@3027000 {
			compatible = "arm,coresight-tmc\0arm,primecell";
			reg = <0x3027000 0x1000>;
			clocks = <0x15 0x08 0x15 0x09>;
			clock-names = "apb_pclk\0atclk";

			in-ports {

				port {

					endpoint {
						remote-endpoint = <0x42>;
						phandle = <0x3e>;
					};
				};
			};

			out-ports {

				port {

					endpoint {
						remote-endpoint = <0x43>;
						phandle = <0x3f>;
					};
				};
			};
		};

		etr@3028000 {
			compatible = "arm,coresight-tmc\0arm,primecell";
			reg = <0x3028000 0x1000>;
			clocks = <0x15 0x08 0x15 0x09>;
			clock-names = "apb_pclk\0atclk";
			arm,scatter-gather;

			in-ports {

				port {

					endpoint {
						remote-endpoint = <0x44>;
						phandle = <0x40>;
					};
				};
			};
		};

		debug@3810000 {
			compatible = "arm,coresight-cpu-debug\0arm,primecell";
			reg = <0x3810000 0x1000>;
			clocks = <0x15 0x08>;
			clock-names = "apb_pclk";
			cpu = <0x08>;
		};

		etm@3840000 {
			compatible = "arm,coresight-etm4x\0arm,primecell";
			reg = <0x3840000 0x1000>;
			clocks = <0x15 0x08 0x15 0x09>;
			clock-names = "apb_pclk\0atclk";
			cpu = <0x08>;

			out-ports {

				port {

					endpoint {
						remote-endpoint = <0x45>;
						phandle = <0x47>;
					};
				};
			};
		};

		debug@3910000 {
			compatible = "arm,coresight-cpu-debug\0arm,primecell";
			reg = <0x3910000 0x1000>;
			clocks = <0x15 0x08>;
			clock-names = "apb_pclk";
			cpu = <0x09>;
		};

		etm@3940000 {
			compatible = "arm,coresight-etm4x\0arm,primecell";
			reg = <0x3940000 0x1000>;
			clocks = <0x15 0x08 0x15 0x09>;
			clock-names = "apb_pclk\0atclk";
			cpu = <0x09>;

			out-ports {

				port {

					endpoint {
						remote-endpoint = <0x46>;
						phandle = <0x48>;
					};
				};
			};
		};

		funnel@39b0000 {
			compatible = "arm,coresight-dynamic-funnel\0arm,primecell";
			reg = <0x39b0000 0x1000>;
			clocks = <0x15 0x08 0x15 0x09>;
			clock-names = "apb_pclk\0atclk";

			in-ports {
				#address-cells = <0x01>;
				#size-cells = <0x00>;

				port@0 {
					reg = <0x00>;

					endpoint {
						remote-endpoint = <0x47>;
						phandle = <0x45>;
					};
				};

				port@1 {
					reg = <0x01>;

					endpoint {
						remote-endpoint = <0x48>;
						phandle = <0x46>;
					};
				};
			};

			out-ports {

				port {

					endpoint {
						remote-endpoint = <0x49>;
						phandle = <0x4f>;
					};
				};
			};
		};

		debug@3a10000 {
			compatible = "arm,coresight-cpu-debug\0arm,primecell";
			reg = <0x3a10000 0x1000>;
			clocks = <0x15 0x08>;
			clock-names = "apb_pclk";
			cpu = <0x0a>;
		};

		etm@3a40000 {
			compatible = "arm,coresight-etm4x\0arm,primecell";
			reg = <0x3a40000 0x1000>;
			clocks = <0x15 0x08 0x15 0x09>;
			clock-names = "apb_pclk\0atclk";
			cpu = <0x0a>;

			out-ports {

				port {

					endpoint {
						remote-endpoint = <0x4a>;
						phandle = <0x4c>;
					};
				};
			};
		};

		debug@3b10000 {
			compatible = "arm,coresight-cpu-debug\0arm,primecell";
			reg = <0x3b10000 0x1000>;
			clocks = <0x15 0x08>;
			clock-names = "apb_pclk";
			cpu = <0x0b>;
		};

		etm@3b40000 {
			compatible = "arm,coresight-etm4x\0arm,primecell";
			reg = <0x3b40000 0x1000>;
			clocks = <0x15 0x08 0x15 0x09>;
			clock-names = "apb_pclk\0atclk";
			cpu = <0x0b>;

			out-ports {

				port {

					endpoint {
						remote-endpoint = <0x4b>;
						phandle = <0x4d>;
					};
				};
			};
		};

		funnel@3bb0000 {
			compatible = "arm,coresight-dynamic-funnel\0arm,primecell";
			reg = <0x3bb0000 0x1000>;
			clocks = <0x15 0x08 0x15 0x09>;
			clock-names = "apb_pclk\0atclk";

			in-ports {
				#address-cells = <0x01>;
				#size-cells = <0x00>;

				port@0 {
					reg = <0x00>;

					endpoint {
						remote-endpoint = <0x4c>;
						phandle = <0x4a>;
					};
				};

				port@1 {
					reg = <0x01>;

					endpoint {
						remote-endpoint = <0x4d>;
						phandle = <0x4b>;
					};
				};
			};

			out-ports {

				port {

					endpoint {
						remote-endpoint = <0x4e>;
						phandle = <0x50>;
					};
				};
			};
		};

		funnel@3bc0000 {
			compatible = "arm,coresight-dynamic-funnel\0arm,primecell";
			reg = <0x3bc0000 0x1000>;
			clocks = <0x15 0x08 0x15 0x09>;
			clock-names = "apb_pclk\0atclk";

			in-ports {
				#address-cells = <0x01>;
				#size-cells = <0x00>;

				port@0 {
					reg = <0x00>;

					endpoint {
						remote-endpoint = <0x4f>;
						phandle = <0x49>;
					};
				};

				port@1 {
					reg = <0x01>;

					endpoint {
						remote-endpoint = <0x50>;
						phandle = <0x4e>;
					};
				};
			};

			out-ports {

				port {

					endpoint {
						remote-endpoint = <0x51>;
						phandle = <0x38>;
					};
				};
			};
		};

		clock-controller@6400000 {
			compatible = "qcom,msm8996-apcc";
			reg = <0x6400000 0x90000>;
			clock-names = "xo";
			clocks = <0x1d>;
			#clock-cells = <0x01>;
			phandle = <0x03>;
		};

		usb@6af8800 {
			compatible = "qcom,msm8996-dwc3\0qcom,dwc3";
			reg = <0x6af8800 0x400>;
			#address-cells = <0x01>;
			#size-cells = <0x01>;
			ranges;
			interrupts = <0x00 0x15b 0x04 0x00 0xf3 0x04>;
			interrupt-names = "hs_phy_irq\0ss_phy_irq";
			clocks = <0x14 0x51 0x14 0x5b 0x14 0xd2 0x14 0x5d 0x14 0x5c 0x14 0x63>;
			assigned-clocks = <0x14 0x5d 0x14 0x5b>;
			assigned-clock-rates = <0x124f800 0x7270e00>;
			power-domains = <0x14 0x04>;
			status = "disabled";
			phandle = <0xa5>;

			dwc3@6a00000 {
				compatible = "snps,dwc3";
				reg = <0x6a00000 0xcc00>;
				interrupts = <0x00 0x83 0x04>;
				phys = <0x52 0x53>;
				phy-names = "usb2-phy\0usb3-phy";
				snps,dis_u2_susphy_quirk;
				snps,dis_enblslpm_quirk;
				phandle = <0xa6>;
			};
		};

		phy@7410000 {
			compatible = "qcom,msm8996-qmp-usb3-phy";
			reg = <0x7410000 0x1c4>;
			#clock-cells = <0x01>;
			#address-cells = <0x01>;
			#size-cells = <0x01>;
			ranges;
			clocks = <0x14 0x5e 0x14 0x63 0x14 0xd5>;
			clock-names = "aux\0cfg_ahb\0ref";
			resets = <0x14 0x67 0x14 0x68>;
			reset-names = "phy\0common";
			status = "disabled";
			phandle = <0xa7>;

			phy@7410200 {
				reg = <0x7410200 0x200 0x7410400 0x130 0x7410600 0x1a8>;
				#phy-cells = <0x00>;
				clock-output-names = "usb3_phy_pipe_clk_src";
				clocks = <0x14 0x5f>;
				clock-names = "pipe0";
				phandle = <0x53>;
			};
		};

		phy@7411000 {
			compatible = "qcom,msm8996-qusb2-phy";
			reg = <0x7411000 0x180>;
			#phy-cells = <0x00>;
			clocks = <0x14 0x63 0x14 0xda>;
			clock-names = "cfg_ahb\0ref";
			resets = <0x14 0x09>;
			nvmem-cells = <0x54>;
			status = "disabled";
			phandle = <0x52>;
		};

		phy@7412000 {
			compatible = "qcom,msm8996-qusb2-phy";
			reg = <0x7412000 0x180>;
			#phy-cells = <0x00>;
			clocks = <0x14 0x63 0x14 0xd9>;
			clock-names = "cfg_ahb\0ref";
			resets = <0x14 0x0a>;
			nvmem-cells = <0x55>;
			status = "disabled";
			phandle = <0x69>;
		};

		sdhci@7464900 {
			compatible = "qcom,sdhci-msm-v4";
			reg = <0x7464900 0x11c 0x7464000 0x800>;
			reg-names = "hc_mem\0core_mem";
			interrupts = <0x00 0x8d 0x04 0x00 0x86 0x04>;
			interrupt-names = "hc_irq\0pwr_irq";
			clock-names = "iface\0core\0xo";
			clocks = <0x14 0x65 0x14 0x64 0x1d>;
			pinctrl-names = "default\0sleep";
			pinctrl-0 = <0x56>;
			pinctrl-1 = <0x57>;
			bus-width = <0x08>;
			non-removable;
			status = "disabled";
			phandle = <0xa8>;
		};

		sdhci@74a4900 {
			compatible = "qcom,sdhci-msm-v4";
			reg = <0x74a4900 0x314 0x74a4000 0x800>;
			reg-names = "hc_mem\0core_mem";
			interrupts = <0x00 0x7d 0x04 0x00 0xdd 0x04>;
			interrupt-names = "hc_irq\0pwr_irq";
			clock-names = "iface\0core\0xo";
			clocks = <0x14 0x68 0x14 0x67 0x1d>;
			pinctrl-names = "default\0sleep";
			pinctrl-0 = <0x58>;
			pinctrl-1 = <0x59>;
			bus-width = <0x04>;
			status = "disabled";
			phandle = <0xa9>;
		};

		dma@7544000 {
			compatible = "qcom,bam-v1.7.0";
			reg = <0x7544000 0x2b000>;
			interrupts = <0x00 0xee 0x04>;
			clocks = <0x14 0x6d>;
			clock-names = "bam_clk";
			qcom,controlled-remotely;
			#dma-cells = <0x01>;
			qcom,ee = <0x00>;
			phandle = <0x5a>;
		};

		serial@7570000 {
			compatible = "qcom,msm-uartdm-v1.4\0qcom,msm-uartdm";
			reg = <0x7570000 0x1000>;
			interrupts = <0x00 0x6c 0x04>;
			clocks = <0x14 0x74 0x14 0x6d>;
			clock-names = "core\0iface";
			dmas = <0x5a 0x02 0x5a 0x03>;
			dma-names = "tx\0rx";
			status = "disabled";
			phandle = <0xaa>;
		};

		spi@7575000 {
			compatible = "qcom,spi-qup-v2.2.1";
			reg = <0x7575000 0x600>;
			interrupts = <0x00 0x5f 0x04>;
			clocks = <0x14 0x6f 0x14 0x6d>;
			clock-names = "core\0iface";
			pinctrl-names = "default\0sleep";
			pinctrl-0 = <0x5b>;
			pinctrl-1 = <0x5c>;
			dmas = <0x5a 0x0c 0x5a 0x0d>;
			dma-names = "tx\0rx";
			#address-cells = <0x01>;
			#size-cells = <0x00>;
			status = "disabled";
			phandle = <0xab>;
		};

		i2c@7577000 {
			compatible = "qcom,i2c-qup-v2.2.1";
			reg = <0x7577000 0x1000>;
			interrupts = <0x00 0x61 0x04>;
			clocks = <0x14 0x6d 0x14 0x76>;
			clock-names = "iface\0core";
			pinctrl-names = "default\0sleep";
			pinctrl-0 = <0x5d>;
			pinctrl-1 = <0x5e>;
			dmas = <0x5a 0x10 0x5a 0x11>;
			dma-names = "tx\0rx";
			#address-cells = <0x01>;
			#size-cells = <0x00>;
			status = "disabled";
			phandle = <0xac>;
		};

		dma@7584000 {
			compatible = "qcom,bam-v1.7.0";
			reg = <0x7584000 0x2b000>;
			interrupts = <0x00 0xef 0x04>;
			clocks = <0x14 0x81>;
			clock-names = "bam_clk";
			qcom,controlled-remotely;
			#dma-cells = <0x01>;
			qcom,ee = <0x00>;
			phandle = <0x61>;
		};

		serial@75b0000 {
			compatible = "qcom,msm-uartdm-v1.4\0qcom,msm-uartdm";
			reg = <0x75b0000 0x1000>;
			interrupts = <0x00 0x72 0x04>;
			clocks = <0x14 0x88 0x14 0x81>;
			clock-names = "core\0iface";
			status = "okay";
			phandle = <0xad>;
		};

		serial@75b1000 {
			compatible = "qcom,msm-uartdm-v1.4\0qcom,msm-uartdm";
			reg = <0x75b1000 0x1000>;
			interrupts = <0x00 0x73 0x04>;
			clocks = <0x14 0x8b 0x14 0x81>;
			clock-names = "core\0iface";
			status = "disabled";
			phandle = <0xae>;
		};

		i2c@75b5000 {
			compatible = "qcom,i2c-qup-v2.2.1";
			reg = <0x75b5000 0x1000>;
			interrupts = <0x00 0x65 0x04>;
			clocks = <0x14 0x81 0x14 0x84>;
			clock-names = "iface\0core";
			pinctrl-names = "default\0sleep";
			pinctrl-0 = <0x5f>;
			pinctrl-1 = <0x60>;
			dmas = <0x61 0x0c 0x61 0x0d>;
			dma-names = "tx\0rx";
			#address-cells = <0x01>;
			#size-cells = <0x00>;
			status = "disabled";
			phandle = <0xaf>;
		};

		i2c@75b6000 {
			compatible = "qcom,i2c-qup-v2.2.1";
			reg = <0x75b6000 0x1000>;
			interrupts = <0x00 0x66 0x04>;
			clocks = <0x14 0x81 0x14 0x87>;
			clock-names = "iface\0core";
			pinctrl-names = "default\0sleep";
			pinctrl-0 = <0x62>;
			pinctrl-1 = <0x63>;
			dmas = <0x61 0x0e 0x61 0x0f>;
			dma-names = "tx\0rx";
			#address-cells = <0x01>;
			#size-cells = <0x00>;
			status = "disabled";
			phandle = <0xb0>;
		};

		i2c@75b9000 {
			compatible = "qcom,i2c-qup-v2.2.1";
			reg = <0x75b9000 0x1000>;
			interrupts = <0x00 0x69 0x04>;
			clocks = <0x14 0x81 0x14 0x90>;
			clock-names = "iface\0core";
			pinctrl-names = "default";
			pinctrl-0 = <0x64>;
			dmas = <0x61 0x14 0x61 0x15>;
			dma-names = "tx\0rx";
			#address-cells = <0x01>;
			#size-cells = <0x00>;
			status = "disabled";
			phandle = <0xb1>;
		};

		i2c@75ba000 {
			compatible = "qcom,i2c-qup-v2.2.1";
			reg = <0x75ba000 0x1000>;
			interrupts = <0x00 0x6a 0x04>;
			clocks = <0x14 0x81 0x14 0x93>;
			clock-names = "iface\0core";
			pinctrl-names = "default\0sleep";
			pinctrl-0 = <0x65>;
			pinctrl-1 = <0x66>;
			dmas = <0x61 0x16 0x61 0x17>;
			dma-names = "tx\0rx";
			#address-cells = <0x01>;
			#size-cells = <0x00>;
			status = "disabled";
			phandle = <0xb2>;
		};

		spi@75ba000 {
			compatible = "qcom,spi-qup-v2.2.1";
			reg = <0x75ba000 0x600>;
			interrupts = <0x00 0x6a 0x04>;
			clocks = <0x14 0x92 0x14 0x81>;
			clock-names = "core\0iface";
			pinctrl-names = "default\0sleep";
			pinctrl-0 = <0x67>;
			pinctrl-1 = <0x68>;
			dmas = <0x61 0x16 0x61 0x17>;
			dma-names = "tx\0rx";
			#address-cells = <0x01>;
			#size-cells = <0x00>;
			status = "disabled";
			phandle = <0xb3>;
		};

		usb@76f8800 {
			compatible = "qcom,msm8996-dwc3\0qcom,dwc3";
			reg = <0x76f8800 0x400>;
			#address-cells = <0x01>;
			#size-cells = <0x01>;
			ranges;
			clocks = <0x14 0x55 0x14 0x60 0x14 0x62 0x14 0x61 0x14 0x63>;
			assigned-clocks = <0x14 0x62 0x14 0x60>;
			assigned-clock-rates = <0x124f800 0x3938700>;
			power-domains = <0x14 0x04>;
			qcom,select-utmi-as-pipe-clk;
			status = "disabled";
			phandle = <0xb4>;

			dwc3@7600000 {
				compatible = "snps,dwc3";
				reg = <0x7600000 0xcc00>;
				interrupts = <0x00 0x8a 0x04>;
				phys = <0x69>;
				phy-names = "usb2-phy";
				maximum-speed = "high-speed";
				snps,dis_u2_susphy_quirk;
				snps,dis_enblslpm_quirk;
			};
		};

		dma-controller@9184000 {
			compatible = "qcom,bam-v1.7.0";
			qcom,controlled-remotely;
			reg = <0x9184000 0x32000>;
			num-channels = <0x1f>;
			interrupts = <0x00 0xa4 0x04>;
			#dma-cells = <0x01>;
			qcom,ee = <0x01>;
			qcom,num-ees = <0x02>;
			phandle = <0x6a>;
		};

		slim@91c0000 {
			compatible = "qcom,slim-ngd-v1.5.0";
			reg = <0x91c0000 0x2c000>;
			reg-names = "ctrl";
			interrupts = <0x00 0xa3 0x04>;
			dmas = <0x6a 0x03 0x6a 0x04 0x6a 0x05 0x6a 0x06>;
			dma-names = "rx\0tx\0tx2\0rx2";
			#address-cells = <0x01>;
			#size-cells = <0x00>;
			phandle = <0xb5>;

			ngd@1 {
				reg = <0x01>;
				#address-cells = <0x01>;
				#size-cells = <0x01>;

				tas-ifd {
					compatible = "slim217,1a0";
					reg = <0x00 0x00>;
					phandle = <0x6d>;
				};

				codec@1 {
					pinctrl-0 = <0x6b 0x6c>;
					pinctrl-names = "default";
					compatible = "slim217,1a0";
					reg = <0x01 0x00>;
					interrupt-parent = <0x23>;
					interrupts = <0x36 0x04 0x35 0x04>;
					interrupt-names = "intr1\0intr2";
					interrupt-controller;
					#interrupt-cells = <0x01>;
					reset-gpios = <0x23 0x40 0x00>;
					slim-ifc-dev = <0x6d>;
					#sound-dai-cells = <0x01>;
					phandle = <0xb6>;
				};
			};
		};

		remoteproc@9300000 {
			compatible = "qcom,msm8996-adsp-pil";
			reg = <0x9300000 0x80000>;
			interrupts-extended = <0x01 0x00 0xa2 0x01 0x6e 0x00 0x01 0x6e 0x01 0x01 0x6e 0x02 0x01 0x6e 0x03 0x01>;
			interrupt-names = "wdog\0fatal\0ready\0handover\0stop-ack";
			clocks = <0x1d>;
			clock-names = "xo";
			memory-region = <0x6f>;
			qcom,smem-states = <0x70 0x00>;
			qcom,smem-state-names = "stop";
			power-domains = <0x71 0x00>;
			power-domain-names = "cx";
			status = "disabled";
			phandle = <0xb7>;

			smd-edge {
				interrupts = <0x00 0x9c 0x01>;
				label = "lpass";
				mboxes = <0x10 0x08>;
				qcom,smd-edge = <0x01>;
				qcom,remote-pid = <0x02>;
				#address-cells = <0x01>;
				#size-cells = <0x00>;

				apr {
					power-domains = <0x14 0x02>;
					compatible = "qcom,apr-v2";
					qcom,smd-channels = "apr_audio_svc";
					qcom,apr-domain = <0x04>;
					#address-cells = <0x01>;
					#size-cells = <0x00>;

					q6core {
						reg = <0x03>;
						compatible = "qcom,q6core";
					};

					q6afe {
						compatible = "qcom,q6afe";
						reg = <0x04>;
						phandle = <0xb8>;

						dais {
							compatible = "qcom,q6afe-dais";
							#address-cells = <0x01>;
							#size-cells = <0x00>;
							#sound-dai-cells = <0x01>;
							phandle = <0xb9>;

							hdmi@1 {
								reg = <0x01>;
							};
						};
					};

					q6asm {
						compatible = "qcom,q6asm";
						reg = <0x07>;
						phandle = <0xba>;

						dais {
							compatible = "qcom,q6asm-dais";
							#address-cells = <0x01>;
							#size-cells = <0x00>;
							#sound-dai-cells = <0x01>;
							iommus = <0x72 0x01>;
							phandle = <0xbb>;
						};
					};

					q6adm {
						compatible = "qcom,q6adm";
						reg = <0x08>;
						phandle = <0xbc>;

						routing {
							compatible = "qcom,q6adm-routing";
							#sound-dai-cells = <0x00>;
							phandle = <0xbd>;
						};
					};
				};
			};
		};

		mailbox@9820000 {
			compatible = "qcom,msm8996-apcs-hmss-global";
			reg = <0x9820000 0x1000>;
			#mbox-cells = <0x01>;
			phandle = <0x10>;
		};

		timer@9840000 {
			#address-cells = <0x01>;
			#size-cells = <0x01>;
			ranges;
			compatible = "arm,armv7-timer-mem";
			reg = <0x9840000 0x1000>;
			clock-frequency = <0x124f800>;

			frame@9850000 {
				frame-number = <0x00>;
				interrupts = <0x00 0x1f 0x04 0x00 0x1e 0x04>;
				reg = <0x9850000 0x1000 0x9860000 0x1000>;
			};

			frame@9870000 {
				frame-number = <0x01>;
				interrupts = <0x00 0x20 0x04>;
				reg = <0x9870000 0x1000>;
				status = "disabled";
			};

			frame@9880000 {
				frame-number = <0x02>;
				interrupts = <0x00 0x21 0x04>;
				reg = <0x9880000 0x1000>;
				status = "disabled";
			};

			frame@9890000 {
				frame-number = <0x03>;
				interrupts = <0x00 0x22 0x04>;
				reg = <0x9890000 0x1000>;
				status = "disabled";
			};

			frame@98a0000 {
				frame-number = <0x04>;
				interrupts = <0x00 0x23 0x04>;
				reg = <0x98a0000 0x1000>;
				status = "disabled";
			};

			frame@98b0000 {
				frame-number = <0x05>;
				interrupts = <0x00 0x24 0x04>;
				reg = <0x98b0000 0x1000>;
				status = "disabled";
			};

			frame@98c0000 {
				frame-number = <0x06>;
				interrupts = <0x00 0x25 0x04>;
				reg = <0x98c0000 0x1000>;
				status = "disabled";
			};
		};

		syscon@9a10000 {
			compatible = "syscon";
			reg = <0x9a10000 0x1000>;
			phandle = <0xbe>;
		};

		interrupt-controller@9bc0000 {
			compatible = "qcom,msm8996-gic-v3\0arm,gic-v3";
			#interrupt-cells = <0x03>;
			interrupt-controller;
			#redistributor-regions = <0x01>;
			redistributor-stride = <0x00 0x40000>;
			reg = <0x9bc0000 0x10000 0x9c00000 0x100000>;
			interrupts = <0x01 0x09 0x04>;
			phandle = <0x01>;
		};
	};

	sound {
		phandle = <0xbf>;
	};

	thermal-zones {

		cpu0-thermal {
			polling-delay-passive = <0xfa>;
			polling-delay = <0x3e8>;
			thermal-sensors = <0x73 0x03>;

			trips {

				trip-point0 {
					temperature = <0x124f8>;
					hysteresis = <0x7d0>;
					type = "passive";
					phandle = <0xc0>;
				};

				cpu_crit {
					temperature = <0x1adb0>;
					hysteresis = <0x7d0>;
					type = "critical";
					phandle = <0xc1>;
				};
			};
		};

		cpu1-thermal {
			polling-delay-passive = <0xfa>;
			polling-delay = <0x3e8>;
			thermal-sensors = <0x73 0x05>;

			trips {

				trip-point0 {
					temperature = <0x124f8>;
					hysteresis = <0x7d0>;
					type = "passive";
					phandle = <0xc2>;
				};

				cpu_crit {
					temperature = <0x1adb0>;
					hysteresis = <0x7d0>;
					type = "critical";
					phandle = <0xc3>;
				};
			};
		};

		cpu2-thermal {
			polling-delay-passive = <0xfa>;
			polling-delay = <0x3e8>;
			thermal-sensors = <0x73 0x08>;

			trips {

				trip-point0 {
					temperature = <0x124f8>;
					hysteresis = <0x7d0>;
					type = "passive";
					phandle = <0xc4>;
				};

				cpu_crit {
					temperature = <0x1adb0>;
					hysteresis = <0x7d0>;
					type = "critical";
					phandle = <0xc5>;
				};
			};
		};

		cpu3-thermal {
			polling-delay-passive = <0xfa>;
			polling-delay = <0x3e8>;
			thermal-sensors = <0x73 0x0a>;

			trips {

				trip-point0 {
					temperature = <0x124f8>;
					hysteresis = <0x7d0>;
					type = "passive";
					phandle = <0xc6>;
				};

				cpu_crit {
					temperature = <0x1adb0>;
					hysteresis = <0x7d0>;
					type = "critical";
					phandle = <0xc7>;
				};
			};
		};

		gpu-thermal-top {
			polling-delay-passive = <0xfa>;
			polling-delay = <0x3e8>;
			thermal-sensors = <0x74 0x06>;

			trips {

				trip-point0 {
					temperature = <0x15f90>;
					hysteresis = <0x7d0>;
					type = "passive";
					phandle = <0x75>;
				};
			};

			cooling-maps {

				map0 {
					trip = <0x75>;
					cooling-device = <0x76 0xffffffff 0xffffffff>;
				};
			};
		};

		gpu-thermal-bottom {
			polling-delay-passive = <0xfa>;
			polling-delay = <0x3e8>;
			thermal-sensors = <0x74 0x07>;

			trips {

				trip-point0 {
					temperature = <0x15f90>;
					hysteresis = <0x7d0>;
					type = "passive";
					phandle = <0x77>;
				};
			};

			cooling-maps {

				map0 {
					trip = <0x77>;
					cooling-device = <0x76 0xffffffff 0xffffffff>;
				};
			};
		};

		m4m-thermal {
			polling-delay-passive = <0xfa>;
			polling-delay = <0x3e8>;
			thermal-sensors = <0x73 0x01>;

			trips {

				trip-point0 {
					temperature = <0x15f90>;
					hysteresis = <0x7d0>;
					type = "hot";
					phandle = <0xc8>;
				};
			};
		};

		l3-or-venus-thermal {
			polling-delay-passive = <0xfa>;
			polling-delay = <0x3e8>;
			thermal-sensors = <0x73 0x02>;

			trips {

				trip-point0 {
					temperature = <0x15f90>;
					hysteresis = <0x7d0>;
					type = "hot";
					phandle = <0xc9>;
				};
			};
		};

		cluster0-l2-thermal {
			polling-delay-passive = <0xfa>;
			polling-delay = <0x3e8>;
			thermal-sensors = <0x73 0x07>;

			trips {

				trip-point0 {
					temperature = <0x15f90>;
					hysteresis = <0x7d0>;
					type = "hot";
					phandle = <0xca>;
				};
			};
		};

		cluster1-l2-thermal {
			polling-delay-passive = <0xfa>;
			polling-delay = <0x3e8>;
			thermal-sensors = <0x73 0x0c>;

			trips {

				trip-point0 {
					temperature = <0x15f90>;
					hysteresis = <0x7d0>;
					type = "hot";
					phandle = <0xcb>;
				};
			};
		};

		camera-thermal {
			polling-delay-passive = <0xfa>;
			polling-delay = <0x3e8>;
			thermal-sensors = <0x74 0x01>;

			trips {

				trip-point0 {
					temperature = <0x15f90>;
					hysteresis = <0x7d0>;
					type = "hot";
					phandle = <0xcc>;
				};
			};
		};

		q6-dsp-thermal {
			polling-delay-passive = <0xfa>;
			polling-delay = <0x3e8>;
			thermal-sensors = <0x74 0x02>;

			trips {

				trip-point0 {
					temperature = <0x15f90>;
					hysteresis = <0x7d0>;
					type = "hot";
					phandle = <0xcd>;
				};
			};
		};

		mem-thermal {
			polling-delay-passive = <0xfa>;
			polling-delay = <0x3e8>;
			thermal-sensors = <0x74 0x03>;

			trips {

				trip-point0 {
					temperature = <0x15f90>;
					hysteresis = <0x7d0>;
					type = "hot";
					phandle = <0xce>;
				};
			};
		};

		modemtx-thermal {
			polling-delay-passive = <0xfa>;
			polling-delay = <0x3e8>;
			thermal-sensors = <0x74 0x04>;

			trips {

				trip-point0 {
					temperature = <0x15f90>;
					hysteresis = <0x7d0>;
					type = "hot";
					phandle = <0xcf>;
				};
			};
		};
	};

	timer {
		compatible = "arm,armv8-timer";
		interrupts = <0x01 0x0d 0x08 0x01 0x0e 0x08 0x01 0x0b 0x08 0x01 0x0a 0x08>;
	};

	aliases {
		serial0 = "/soc/serial@75b0000";
	};

	__symbols__ {
		xo_board = "/clocks/xo-board";
		sleep_clk = "/clocks/sleep-clk";
		CPU0 = "/cpus/cpu@0";
		L2_0 = "/cpus/cpu@0/l2-cache";
		CPU1 = "/cpus/cpu@1";
		CPU2 = "/cpus/cpu@100";
		L2_1 = "/cpus/cpu@100/l2-cache";
		CPU3 = "/cpus/cpu@101";
		CPU_SLEEP_0 = "/cpus/idle-states/cpu-sleep-0";
		cluster0_opp = "/opp_table0";
		cluster1_opp = "/opp_table1";
		tcsr_mutex = "/hwlock";
		mba_region = "/reserved-memory/mba@91500000";
		slpi_region = "/reserved-memory/slpi@90b00000";
		venus_region = "/reserved-memory/venus@90400000";
		adsp_region = "/reserved-memory/adsp@8ea00000";
		mpss_region = "/reserved-memory/mpss@88800000";
		smem_mem = "/reserved-memory/smem-mem@86000000";
		zap_shader_region = "/reserved-memory/gpu@8f200000";
		rpm_requests = "/rpm-glink/rpm-requests";
		rpmcc = "/rpm-glink/rpm-requests/qcom,rpmcc";
		rpmpd = "/rpm-glink/rpm-requests/power-controller";
		rpmpd_opp_table = "/rpm-glink/rpm-requests/power-controller/opp-table";
		rpmpd_opp1 = "/rpm-glink/rpm-requests/power-controller/opp-table/opp1";
		rpmpd_opp2 = "/rpm-glink/rpm-requests/power-controller/opp-table/opp2";
		rpmpd_opp3 = "/rpm-glink/rpm-requests/power-controller/opp-table/opp3";
		rpmpd_opp4 = "/rpm-glink/rpm-requests/power-controller/opp-table/opp4";
		rpmpd_opp5 = "/rpm-glink/rpm-requests/power-controller/opp-table/opp5";
		rpmpd_opp6 = "/rpm-glink/rpm-requests/power-controller/opp-table/opp6";
		smp2p_adsp_out = "/smp2p-adsp/master-kernel";
		smp2p_adsp_in = "/smp2p-adsp/slave-kernel";
		modem_smp2p_out = "/smp2p-modem/master-kernel";
		modem_smp2p_in = "/smp2p-modem/slave-kernel";
		smp2p_slpi_in = "/smp2p-slpi/slave-kernel";
		smp2p_slpi_out = "/smp2p-slpi/master-kernel";
		soc = "/soc";
		pcie_phy = "/soc/phy@34000";
		pciephy_0 = "/soc/phy@34000/phy@35000";
		pciephy_1 = "/soc/phy@34000/phy@36000";
		pciephy_2 = "/soc/phy@34000/phy@37000";
		rpm_msg_ram = "/soc/sram@68000";
		qusb2p_hstx_trim = "/soc/qfprom@74000/hstx_trim@24e";
		qusb2s_hstx_trim = "/soc/qfprom@74000/hstx_trim@24f";
		speedbin_efuse = "/soc/qfprom@74000/speedbin@133";
		rng = "/soc/rng@83000";
		gcc = "/soc/clock-controller@300000";
		tsens0 = "/soc/thermal-sensor@4a9000";
		tsens1 = "/soc/thermal-sensor@4ad000";
		tcsr_mutex_regs = "/soc/syscon@740000";
		tcsr = "/soc/syscon@7a0000";
		mmcc = "/soc/clock-controller@8c0000";
		mdss = "/soc/mdss@900000";
		mdp = "/soc/mdss@900000/mdp@901000";
		mdp5_intf3_out = "/soc/mdss@900000/mdp@901000/ports/port@0/endpoint";
		mdp5_intf1_out = "/soc/mdss@900000/mdp@901000/ports/port@1/endpoint";
		dsi0 = "/soc/mdss@900000/dsi@994000";
		dsi0_in = "/soc/mdss@900000/dsi@994000/ports/port@0/endpoint";
		dsi0_out = "/soc/mdss@900000/dsi@994000/ports/port@1/endpoint";
		dsi0_phy = "/soc/mdss@900000/dsi-phy@994400";
		hdmi = "/soc/mdss@900000/hdmi-tx@9a0000";
		hdmi_in = "/soc/mdss@900000/hdmi-tx@9a0000/ports/port@0/endpoint";
		hdmi_phy = "/soc/mdss@900000/hdmi-phy@9a0600";
		gpu = "/soc/gpu@b00000";
		gpu_opp_table = "/soc/gpu@b00000/opp-table";
		tlmm = "/soc/pinctrl@1010000";
		blsp1_spi1_default = "/soc/pinctrl@1010000/blsp1-spi1-default";
		blsp1_spi1_sleep = "/soc/pinctrl@1010000/blsp1-spi1-sleep";
		blsp2_uart2_2pins_default = "/soc/pinctrl@1010000/blsp2-uart1-2pins";
		blsp2_uart2_2pins_sleep = "/soc/pinctrl@1010000/blsp2-uart1-2pins-sleep";
		blsp2_i2c2_default = "/soc/pinctrl@1010000/blsp2-i2c2";
		blsp2_i2c2_sleep = "/soc/pinctrl@1010000/blsp2-i2c2-sleep";
		cci0_default = "/soc/pinctrl@1010000/cci0-default";
		camera0_state_on = "/soc/pinctrl@1010000/camera-rear-default";
		camera_rear_default = "/soc/pinctrl@1010000/camera-rear-default";
		camera0_mclk = "/soc/pinctrl@1010000/camera-rear-default/mclk0";
		camera0_rst = "/soc/pinctrl@1010000/camera-rear-default/rst";
		camera0_pwdn = "/soc/pinctrl@1010000/camera-rear-default/pwdn";
		cci1_default = "/soc/pinctrl@1010000/cci1-default";
		camera1_state_on = "/soc/pinctrl@1010000/camera-board-default";
		camera_board_default = "/soc/pinctrl@1010000/camera-board-default";
		camera2_state_on = "/soc/pinctrl@1010000/camera-front-default";
		camera_front_default = "/soc/pinctrl@1010000/camera-front-default";
		camera2_mclk = "/soc/pinctrl@1010000/camera-front-default/mclk2";
		camera2_rst = "/soc/pinctrl@1010000/camera-front-default/rst";
		pcie0_state_on = "/soc/pinctrl@1010000/pcie0-state-on";
		pcie0_state_off = "/soc/pinctrl@1010000/pcie0-state-off";
		blsp1_i2c3_default = "/soc/pinctrl@1010000/blsp1-i2c2-default";
		blsp1_i2c3_sleep = "/soc/pinctrl@1010000/blsp1-i2c2-sleep";
		blsp2_uart3_4pins_default = "/soc/pinctrl@1010000/blsp2-uart2-4pins";
		blsp2_uart3_4pins_sleep = "/soc/pinctrl@1010000/blsp2-uart2-4pins-sleep";
		wcd_intr_default = "/soc/pinctrl@1010000/wcd-intr-default";
		blsp2_i2c1_default = "/soc/pinctrl@1010000/blsp2-i2c1";
		blsp2_i2c1_sleep = "/soc/pinctrl@1010000/blsp2-i2c0-sleep";
		blsp2_i2c5_default = "/soc/pinctrl@1010000/blsp2-i2c5";
		cdc_reset_active = "/soc/pinctrl@1010000/cdc-reset-active";
		cdc_reset_sleep = "/soc/pinctrl@1010000/cdc-reset-sleep";
		blsp2_spi6_default = "/soc/pinctrl@1010000/blsp2-spi5-default";
		blsp2_spi6_sleep = "/soc/pinctrl@1010000/blsp2-spi5-sleep";
		blsp2_i2c6_default = "/soc/pinctrl@1010000/blsp2-i2c6";
		blsp2_i2c6_sleep = "/soc/pinctrl@1010000/blsp2-i2c6-sleep";
		pcie1_state_on = "/soc/pinctrl@1010000/pcie1-state-on";
		pcie1_state_off = "/soc/pinctrl@1010000/pcie1-state-off";
		pcie2_state_on = "/soc/pinctrl@1010000/pcie2-state-on";
		pcie2_state_off = "/soc/pinctrl@1010000/pcie2-state-off";
		sdc1_state_on = "/soc/pinctrl@1010000/sdc1-state-on";
		sdc1_state_off = "/soc/pinctrl@1010000/sdc1-state-off";
		sdc2_state_on = "/soc/pinctrl@1010000/sdc2-clk-on";
		sdc2_state_off = "/soc/pinctrl@1010000/sdc2-clk-off";
		spmi_bus = "/soc/qcom,spmi@400f000";
		pcie0 = "/soc/agnoc@0/pcie@600000";
		pcie1 = "/soc/agnoc@0/pcie@608000";
		pcie2 = "/soc/agnoc@0/pcie@610000";
		ufshc = "/soc/ufshc@624000";
		ufsphy = "/soc/phy@627000";
		ufsphy_lane = "/soc/phy@627000/phy@627400";
		camss = "/soc/camss@a00000";
		cci = "/soc/cci@a0c000";
		cci_i2c0 = "/soc/cci@a0c000/i2c-bus@0";
		cci_i2c1 = "/soc/cci@a0c000/i2c-bus@1";
		adreno_smmu = "/soc/iommu@b40000";
		venus = "/soc/video-codec@c00000";
		mdp_smmu = "/soc/iommu@d00000";
		venus_smmu = "/soc/iommu@d40000";
		vfe_smmu = "/soc/iommu@da0000";
		lpass_q6_smmu = "/soc/iommu@1600000";
		stm_out = "/soc/stm@3002000/out-ports/port/endpoint";
		tpiu_in = "/soc/tpiu@3020000/in-ports/port/endpoint";
		funnel0_in = "/soc/funnel@3021000/in-ports/port@7/endpoint";
		funnel0_out = "/soc/funnel@3021000/out-ports/port/endpoint";
		funnel1_in = "/soc/funnel@3022000/in-ports/port@6/endpoint";
		funnel1_out = "/soc/funnel@3022000/out-ports/port/endpoint";
		funnel2_out = "/soc/funnel@3023000/out-ports/port/endpoint";
		merge_funnel_in0 = "/soc/funnel@3025000/in-ports/port@0/endpoint";
		merge_funnel_in1 = "/soc/funnel@3025000/in-ports/port@1/endpoint";
		merge_funnel_in2 = "/soc/funnel@3025000/in-ports/port@2/endpoint";
		merge_funnel_out = "/soc/funnel@3025000/out-ports/port/endpoint";
		replicator_in = "/soc/replicator@3026000/in-ports/port/endpoint";
		replicator_out0 = "/soc/replicator@3026000/out-ports/port@0/endpoint";
		replicator_out1 = "/soc/replicator@3026000/out-ports/port@1/endpoint";
		etf_in = "/soc/etf@3027000/in-ports/port/endpoint";
		etf_out = "/soc/etf@3027000/out-ports/port/endpoint";
		etr_in = "/soc/etr@3028000/in-ports/port/endpoint";
		etm0_out = "/soc/etm@3840000/out-ports/port/endpoint";
		etm1_out = "/soc/etm@3940000/out-ports/port/endpoint";
		apss_funnel0_in0 = "/soc/funnel@39b0000/in-ports/port@0/endpoint";
		apss_funnel0_in1 = "/soc/funnel@39b0000/in-ports/port@1/endpoint";
		apss_funnel0_out = "/soc/funnel@39b0000/out-ports/port/endpoint";
		etm2_out = "/soc/etm@3a40000/out-ports/port/endpoint";
		etm3_out = "/soc/etm@3b40000/out-ports/port/endpoint";
		apss_funnel1_in0 = "/soc/funnel@3bb0000/in-ports/port@0/endpoint";
		apss_funnel1_in1 = "/soc/funnel@3bb0000/in-ports/port@1/endpoint";
		apss_funnel1_out = "/soc/funnel@3bb0000/out-ports/port/endpoint";
		apss_merge_funnel_in0 = "/soc/funnel@3bc0000/in-ports/port@0/endpoint";
		apss_merge_funnel_in1 = "/soc/funnel@3bc0000/in-ports/port@1/endpoint";
		apss_merge_funnel_out = "/soc/funnel@3bc0000/out-ports/port/endpoint";
		kryocc = "/soc/clock-controller@6400000";
		usb3 = "/soc/usb@6af8800";
		usb3_dwc3 = "/soc/usb@6af8800/dwc3@6a00000";
		usb3phy = "/soc/phy@7410000";
		ssusb_phy_0 = "/soc/phy@7410000/phy@7410200";
		hsusb_phy1 = "/soc/phy@7411000";
		hsusb_phy2 = "/soc/phy@7412000";
		sdhc1 = "/soc/sdhci@7464900";
		sdhc2 = "/soc/sdhci@74a4900";
		blsp1_dma = "/soc/dma@7544000";
		blsp1_uart2 = "/soc/serial@7570000";
		blsp1_spi1 = "/soc/spi@7575000";
		blsp1_i2c3 = "/soc/i2c@7577000";
		blsp2_dma = "/soc/dma@7584000";
		blsp2_uart2 = "/soc/serial@75b0000";
		blsp2_uart3 = "/soc/serial@75b1000";
		blsp2_i2c1 = "/soc/i2c@75b5000";
		blsp2_i2c2 = "/soc/i2c@75b6000";
		blsp2_i2c5 = "/soc/i2c@75b9000";
		blsp2_i2c6 = "/soc/i2c@75ba000";
		blsp2_spi6 = "/soc/spi@75ba000";
		usb2 = "/soc/usb@76f8800";
		slimbam = "/soc/dma-controller@9184000";
		slim_msm = "/soc/slim@91c0000";
		tasha_ifd = "/soc/slim@91c0000/ngd@1/tas-ifd";
		wcd9335 = "/soc/slim@91c0000/ngd@1/codec@1";
		adsp_pil = "/soc/remoteproc@9300000";
		q6afe = "/soc/remoteproc@9300000/smd-edge/apr/q6afe";
		q6afedai = "/soc/remoteproc@9300000/smd-edge/apr/q6afe/dais";
		q6asm = "/soc/remoteproc@9300000/smd-edge/apr/q6asm";
		q6asmdai = "/soc/remoteproc@9300000/smd-edge/apr/q6asm/dais";
		q6adm = "/soc/remoteproc@9300000/smd-edge/apr/q6adm";
		q6routing = "/soc/remoteproc@9300000/smd-edge/apr/q6adm/routing";
		apcs_glb = "/soc/mailbox@9820000";
		saw3 = "/soc/syscon@9a10000";
		intc = "/soc/interrupt-controller@9bc0000";
		sound = "/sound";
		cpu0_alert0 = "/thermal-zones/cpu0-thermal/trips/trip-point0";
		cpu0_crit = "/thermal-zones/cpu0-thermal/trips/cpu_crit";
		cpu1_alert0 = "/thermal-zones/cpu1-thermal/trips/trip-point0";
		cpu1_crit = "/thermal-zones/cpu1-thermal/trips/cpu_crit";
		cpu2_alert0 = "/thermal-zones/cpu2-thermal/trips/trip-point0";
		cpu2_crit = "/thermal-zones/cpu2-thermal/trips/cpu_crit";
		cpu3_alert0 = "/thermal-zones/cpu3-thermal/trips/trip-point0";
		cpu3_crit = "/thermal-zones/cpu3-thermal/trips/cpu_crit";
		gpu1_alert0 = "/thermal-zones/gpu-thermal-top/trips/trip-point0";
		gpu2_alert0 = "/thermal-zones/gpu-thermal-bottom/trips/trip-point0";
		m4m_alert0 = "/thermal-zones/m4m-thermal/trips/trip-point0";
		l3_or_venus_alert0 = "/thermal-zones/l3-or-venus-thermal/trips/trip-point0";
		cluster0_l2_alert0 = "/thermal-zones/cluster0-l2-thermal/trips/trip-point0";
		cluster1_l2_alert0 = "/thermal-zones/cluster1-l2-thermal/trips/trip-point0";
		camera_alert0 = "/thermal-zones/camera-thermal/trips/trip-point0";
		q6_dsp_alert0 = "/thermal-zones/q6-dsp-thermal/trips/trip-point0";
		mem_alert0 = "/thermal-zones/mem-thermal/trips/trip-point0";
		modemtx_alert0 = "/thermal-zones/modemtx-thermal/trips/trip-point0";
	};
};
